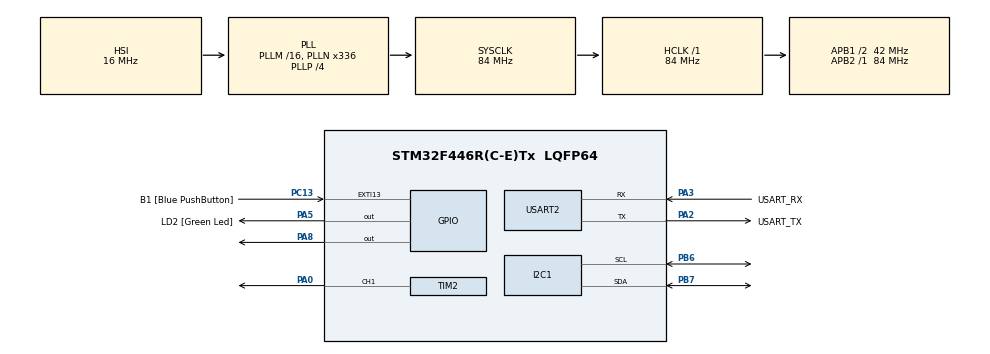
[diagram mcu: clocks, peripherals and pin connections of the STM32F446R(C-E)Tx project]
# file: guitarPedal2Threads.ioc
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FREERTOS.Tasks01=blinker,24,128,StartBlinker,Default,NULL,Dynamic,NULL,NULL;oled,8,128,StartOled,Default,NULL,Dynamic,NULL,NULL
FREERTOS.configTICK_RATE_HZ=1000
I2C1.I2C_Mode=I2C_Fast
Mcu.Family=STM32F4
Mcu.Name=STM32F446R(C-E)Tx
Mcu.Package=LQFP64
NVIC.PriorityGroup=NVIC_PRIORITYGROUP_4
NVIC.TIM6_DAC_IRQn=true\:15\:0\:false\:false\:true\:false\:false\:true\:true
NVIC.TimeBase=TIM6_DAC_IRQn
NVIC.TimeBaseIP=TIM6
PA0-WKUP.Signal=S_TIM2_CH1_ETR
PA13.GPIO_Label=TMS
PA13.Mode=Serial_Wire
PA13.Signal=SYS_JTMS-SWDIO
PA14.GPIO_Label=TCK
PA14.Mode=Serial_Wire
PA14.Signal=SYS_JTCK-SWCLK
PA2.GPIO_Label=USART_TX
PA2.Mode=Asynchronous
PA2.Signal=USART2_TX
PA3.GPIO_Label=USART_RX
PA3.Mode=Asynchronous
PA3.Signal=USART2_RX
PA5.GPIO_Label=LD2 [Green Led]
PA5.Signal=GPIO_Output
PA8.Signal=GPIO_Output
PB3.GPIO_Label=SWO
PB3.Signal=SYS_JTDO-SWO
PB6.Mode=I2C
PB6.Signal=I2C1_SCL
PB7.Mode=I2C
PB7.Signal=I2C1_SDA
PC13.GPIO_Label=B1 [Blue PushButton]
PC13.GPIO_ModeDefaultEXTI=GPIO_MODE_IT_FALLING
PC13.Signal=GPXTI13
PC14-OSC32_IN.Mode=LSE-External-Oscillator
PC14-OSC32_IN.Signal=RCC_OSC32_IN
PC15-OSC32_OUT.Mode=LSE-External-Oscillator
PC15-OSC32_OUT.Signal=RCC_OSC32_OUT
PH0-OSC_IN.Mode=HSE-External-Oscillator
PH0-OSC_IN.Signal=RCC_OSC_IN
PH1-OSC_OUT.Mode=HSE-External-Oscillator
PH1-OSC_OUT.Signal=RCC_OSC_OUT
ProjectManager.HeapSize=0x200
ProjectManager.StackSize=0x400
ProjectManager.TargetToolchain=STM32CubeIDE
RCC.48MHZClocksFreq_Value=84000000
RCC.AHBFreq_Value=84000000
RCC.APB1CLKDivider=RCC_HCLK_DIV2
RCC.APB1Freq_Value=42000000
RCC.APB1TimFreq_Value=84000000
RCC.APB2Freq_Value=84000000
RCC.APB2TimFreq_Value=84000000
RCC.CortexFreq_Value=84000000
RCC.FLatency-AdvancedSettings=FLASH_LATENCY_2
RCC.HCLKFreq_Value=84000000
RCC.HSE_VALUE=8000000
RCC.HSI_VALUE=16000000
RCC.PLLN=336
RCC.PLLP=RCC_PLLP_DIV4
RCC.SYSCLKFreq_VALUE=84000000
RCC.SYSCLKSource=RCC_SYSCLKSOURCE_PLLCLK
RCC.USBFreq_Value=168000000
RCC.VCOOutputFreq_Value=336000000
SH.S_TIM2_CH1_ETR.0=TIM2_CH1,PWM Generation1 CH1
TIM2.AutoReloadPreload=TIM_AUTORELOAD_PRELOAD_ENABLE
TIM2.Channel-PWM\ Generation1\ CH1=TIM_CHANNEL_1
TIM2.Period=255
TIM2.Pulse-PWM\ Generation1\ CH1=123
USART2.VirtualMode=VM_ASYNC
VP_FREERTOS_VS_CMSIS_V2.Mode=CMSIS_V2
VP_SYS_VS_tim6.Mode=TIM6
VP_TIM2_VS_ClockSourceINT.Mode=Internal
board=NUCLEO-F446RE

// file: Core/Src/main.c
/* USER CODE BEGIN Header */
/**
  ******************************************************************************
  * @file           : main.c
  * @brief          : Main program body
  ******************************************************************************
  * @attention
  *
  * Copyright (c) 2024 STMicroelectronics.
  * All rights reserved.
  *
  * This software is licensed under terms that can be found in the LICENSE file
  * in the root directory of this software component.
  * If no LICENSE file comes with this software, it is provided AS-IS.
  *
  ******************************************************************************
  */
/* USER CODE END Header */
#include "main.h"
#include "cmsis_os.h"

/* USER CODE BEGIN Includes */
#include "ssd1306.h"
#include "ssd1306_tests.h"
/* USER CODE END Includes */

I2C_HandleTypeDef hi2c1;

TIM_HandleTypeDef htim2;

UART_HandleTypeDef huart2;

/* Definitions for blinker */
osThreadId_t blinkerHandle;
const osThreadAttr_t blinker_attributes = {
  .name = "blinker",
  .stack_size = 128 * 4,
  .priority = (osPriority_t) osPriorityNormal,
};
/* Definitions for oled */
osThreadId_t oledHandle;
const osThreadAttr_t oled_attributes = {
  .name = "oled",
  .stack_size = 128 * 4,
  .priority = (osPriority_t) osPriorityLow,
};

const unsigned char epd_bitmap_catFrame0 []  = {
	0x00, 0x00, 0x00, 0x00, 0x00, 0x00, 0x00, 0x00, 0x00, 0x00, 0x00, 0x00, 0x07, 0x00, 0x00, 0x00,
	0x00, 0x00, 0x00, 0x00, 0x00, 0x00, 0x00, 0x00, 0x00, 0x00, 0x00, 0x00, 0x0f, 0x80, 0x00, 0x00,
	0x00, 0x00, 0x00, 0x00, 0x00, 0x00, 0x00, 0x00, 0x00, 0x00, 0x00, 0x00, 0x0f, 0x80, 0x00, 0x00,
	0x00, 0x00, 0x00, 0x00, 0x00, 0x00, 0x00, 0x00, 0x00, 0x00, 0x00, 0x00, 0x07, 0x00, 0x00, 0x00,
	0x00, 0x00, 0x00, 0x00, 0x00, 0x00, 0x00, 0x00, 0x00, 0x00, 0x00, 0x00, 0x00, 0x00, 0x00, 0x00,
	0x00, 0x00, 0x00, 0x00, 0x00, 0x00, 0x00, 0x00, 0x00, 0x00, 0x00, 0x00, 0x00, 0x00, 0x00, 0x00,
	0x00, 0x00, 0x00, 0x00, 0x00, 0x00, 0x00, 0x00, 0x00, 0x00, 0x00, 0x00, 0x00, 0x00, 0x00, 0x00,
	0x00, 0x00, 0x00, 0x00, 0x00, 0x00, 0x00, 0x00, 0x00, 0x00, 0x00, 0x00, 0x00, 0x00, 0x00, 0x00,
	0x00, 0x00, 0x00, 0x00, 0x00, 0x00, 0x00, 0x00, 0x00, 0x00, 0x00, 0x00, 0x00, 0x00, 0x00, 0x00,
	0x00, 0x00, 0x00, 0x00, 0x00, 0x00, 0x00, 0x00, 0x00, 0x00, 0x00, 0x00, 0x00, 0x00, 0x00, 0x00,
	0x00, 0x00, 0x00, 0x00, 0x00, 0x00, 0x00, 0x00, 0x00, 0x00, 0x00, 0x00, 0x00, 0x00, 0x00, 0x00,
	0x00, 0x00, 0x01, 0xff, 0xff, 0xf0, 0x00, 0x00, 0x00, 0x00, 0x00, 0x00, 0x00, 0x00, 0x00, 0x00,
	0x00, 0x00, 0x07, 0xff, 0xff, 0xf0, 0x00, 0x00, 0x00, 0x00, 0x00, 0x00, 0x00, 0x00, 0x00, 0x00,
	0xff, 0xff, 0xff, 0xff, 0xff, 0xcf, 0xff, 0xff, 0xff, 0xff, 0xff, 0xf8, 0x00, 0x00, 0x00, 0x00,
	0xff, 0xff, 0xff, 0xff, 0xff, 0xcf, 0xff, 0xff, 0xff, 0xff, 0xff, 0xf8, 0x00, 0x00, 0x00, 0x00,
	0xff, 0xff, 0xff, 0xff, 0xfe, 0x7f, 0xff, 0xff, 0xff, 0xff, 0xff, 0xfe, 0x00, 0x00, 0x00, 0x00,
	0xff, 0xff, 0xff, 0xff, 0xfe, 0x3f, 0xff, 0xff, 0xff, 0xff, 0xff, 0xff, 0x00, 0x00, 0x00, 0x00,
	0xff, 0xff, 0xff, 0xff, 0xfe, 0x7f, 0xff, 0xff, 0xff, 0xff, 0xff, 0xff, 0x00, 0x00, 0x00, 0x00,
	0xff, 0xff, 0xff, 0xff, 0xfe, 0x3f, 0xff, 0xff, 0xff, 0xff, 0xff, 0xff, 0x00, 0x00, 0x00, 0x00,
	0xff, 0xff, 0xff, 0xff, 0xfe, 0x3f, 0xff, 0xff, 0xff, 0xff, 0xff, 0xff, 0x00, 0x00, 0x00, 0x00,
	0xff, 0xff, 0xff, 0xff, 0xfe, 0x7f, 0xff, 0xff, 0xff, 0x8f, 0xff, 0xff, 0x00, 0x00, 0x00, 0x00,
	0xff, 0xff, 0xff, 0xff, 0xfe, 0x3f, 0xff, 0xff, 0xff, 0x83, 0xff, 0xff, 0x00, 0x00, 0x00, 0x00,
	0xff, 0xff, 0xff, 0xff, 0xfe, 0x7f, 0xff, 0xff, 0xff, 0xd3, 0xff, 0xff, 0x05, 0x40, 0x00, 0x00,
	0xff, 0xff, 0xff, 0xff, 0xfe, 0x3f, 0xff, 0xff, 0xfc, 0xfe, 0x7f, 0xff, 0x07, 0xe0, 0x00, 0x00,
	0xff, 0xff, 0xff, 0xff, 0xfe, 0x7f, 0xff, 0xff, 0xfc, 0xfe, 0xff, 0xff, 0x0f, 0xe0, 0x00, 0x00,
	0xff, 0xff, 0xff, 0xff, 0xfe, 0x7f, 0xff, 0xff, 0xfc, 0xff, 0xdf, 0xff, 0x3f, 0xe0, 0x00, 0x00,
	0xff, 0xff, 0xff, 0xff, 0xff, 0x7f, 0xff, 0xff, 0xfc, 0xff, 0xdf, 0xff, 0x3f, 0xe0, 0x00, 0x00,
	0xff, 0xff, 0xff, 0xff, 0xff, 0x3f, 0xff, 0xff, 0xfc, 0xff, 0xff, 0xff, 0xff, 0xe0, 0x00, 0x00,
	0xff, 0xff, 0xff, 0xc3, 0xff, 0x7f, 0xff, 0xff, 0xfc, 0xff, 0xf0, 0x01, 0xff, 0xe0, 0x00, 0x00,
	0xff, 0xff, 0xff, 0xc3, 0xff, 0x7f, 0xff, 0xff, 0xfc, 0xff, 0xf0, 0x01, 0xff, 0xe0, 0x00, 0x00,
	0xff, 0xff, 0xff, 0xff, 0xff, 0x3f, 0xff, 0xff, 0xfc, 0xff, 0xff, 0xff, 0xff, 0xc0, 0x00, 0x00,
	0xff, 0xff, 0xfe, 0x7e, 0x7f, 0x7f, 0xff, 0xff, 0xfc, 0xff, 0xff, 0xff, 0xff, 0xc0, 0x00, 0x00,
	0xff, 0xff, 0xfe, 0x7e, 0x7e, 0x3f, 0xff, 0xff, 0xff, 0xff, 0xff, 0xff, 0xff, 0xf8, 0x00, 0x00,
	0xff, 0xff, 0xfe, 0x7e, 0x00, 0x7f, 0xff, 0xff, 0xe3, 0xff, 0xff, 0xff, 0xff, 0xfc, 0x00, 0x00,
	0xff, 0xff, 0xfe, 0x7e, 0x00, 0x7f, 0xff, 0xff, 0xe3, 0xff, 0xff, 0xff, 0xff, 0xfc, 0x00, 0x00,
	0xff, 0xff, 0xff, 0xff, 0xfe, 0x3f, 0xff, 0xff, 0xe3, 0xff, 0xdf, 0xff, 0xfd, 0xfc, 0x00, 0x00,
	0xff, 0xff, 0xff, 0xcf, 0xfe, 0x7f, 0xff, 0xff, 0xe3, 0xff, 0xcf, 0xff, 0xf9, 0xfc, 0x00, 0x00,
	0xff, 0xff, 0xff, 0xdf, 0xfe, 0x7f, 0xff, 0xff, 0xe3, 0xff, 0xcf, 0xff, 0xf9, 0xfc, 0x00, 0x00,
	0xff, 0xff, 0xff, 0xf0, 0x7e, 0x7f, 0xff, 0xff, 0xe3, 0xfe, 0x0f, 0xf1, 0xc1, 0xfc, 0x00, 0x00,
	0xff, 0xff, 0xff, 0xf0, 0x7e, 0x7f, 0xff, 0xff, 0xe3, 0xfe, 0x0f, 0xf1, 0xc1, 0xfc, 0x00, 0x00,
	0xff, 0xff, 0xff, 0xf8, 0x7e, 0x7f, 0xff, 0xff, 0xe3, 0xff, 0xff, 0xff, 0xff, 0xfc, 0x00, 0x00,
	0xff, 0xff, 0xff, 0xff, 0xc0, 0x7f, 0xff, 0xff, 0xe3, 0xff, 0xff, 0xff, 0xff, 0xfc, 0x00, 0x00,
	0xff, 0xff, 0xff, 0xff, 0xf8, 0x7f, 0xff, 0xff, 0xe3, 0xff, 0xff, 0xff, 0xff, 0xfc, 0x00, 0x00,
	0xff, 0xff, 0xff, 0xff, 0xfe, 0x7f, 0xff, 0xff, 0xe3, 0xff, 0xcf, 0xcf, 0xc7, 0xfc, 0x00, 0x00,
	0xff, 0xff, 0xff, 0xff, 0xfe, 0x7f, 0xff, 0xff, 0xe3, 0xff, 0xcf, 0xcf, 0xc7, 0xfc, 0x00, 0x00,
	0xff, 0xff, 0xff, 0xff, 0xfe, 0x7f, 0xff, 0xff, 0xfe, 0xff, 0xc0, 0x00, 0x07, 0xe0, 0x00, 0x00,
	0xff, 0xff, 0xff, 0xff, 0xfe, 0x7f, 0xff, 0xff, 0xfc, 0xff, 0xc0, 0x00, 0x07, 0xc0, 0x00, 0x00,
	0xff, 0xff, 0xff, 0xff, 0xfe, 0x7f, 0xff, 0xff, 0xfe, 0xff, 0xff, 0xff, 0xff, 0xc0, 0x00, 0x00,
	0xff, 0xff, 0xff, 0xff, 0xf0, 0x7f, 0xff, 0xff, 0xff, 0x9f, 0xff, 0xff, 0xff, 0x00, 0x00, 0x00,
	0xff, 0xff, 0xff, 0xff, 0xf0, 0x7f, 0xff, 0xff, 0xff, 0x9f, 0xff, 0xff, 0xff, 0x00, 0x00, 0x00,
	0xff, 0xff, 0xff, 0xff, 0xce, 0x0f, 0xff, 0xff, 0xff, 0xf0, 0x00, 0x00, 0x00, 0x00, 0x00, 0x00,
	0xff, 0xff, 0xff, 0xff, 0xce, 0x0f, 0xff, 0xff, 0xff, 0xf0, 0x00, 0x00, 0x00, 0x00, 0x00, 0x00,
	0xff, 0xff, 0xff, 0xff, 0x8f, 0x0f, 0xff, 0xff, 0xff, 0xff, 0xff, 0xf8, 0x00, 0x00, 0x00, 0x00,
	0xff, 0xff, 0xff, 0xfe, 0x7f, 0xc7, 0xff, 0xff, 0xff, 0xff, 0xff, 0xfe, 0x00, 0x00, 0x00, 0x00,
	0xff, 0xff, 0xff, 0xfc, 0x7f, 0xc0, 0x00, 0x00, 0x00, 0x00, 0x00, 0x06, 0x00, 0x00, 0x00, 0x00,
	0xff, 0xff, 0xff, 0xfe, 0x7f, 0xc0, 0xf8, 0x00, 0x00, 0x0f, 0x80, 0x3e, 0x00, 0x00, 0x00, 0x00,
	0xff, 0xff, 0xfe, 0x00, 0x7e, 0x01, 0xf8, 0x00, 0x00, 0x1f, 0xc0, 0x7e, 0x00, 0x00, 0x00, 0x00,
	0xff, 0xff, 0xf8, 0x00, 0x3e, 0x01, 0xf8, 0x00, 0x00, 0x1f, 0xc0, 0x3e, 0x00, 0x00, 0x00, 0x00,
	0x00, 0x00, 0x00, 0x00, 0x00, 0x00, 0x00, 0x00, 0x00, 0x00, 0x00, 0x00, 0x00, 0x00, 0x00, 0x00,
	0x00, 0x00, 0x00, 0x00, 0x00, 0x00, 0x00, 0x00, 0x00, 0x00, 0x00, 0x00, 0x00, 0x00, 0x00, 0x00,
	0x00, 0x00, 0x00, 0x00, 0x00, 0x00, 0x00, 0x00, 0x00, 0x00, 0x00, 0x00, 0x00, 0x00, 0x00, 0x00,
	0x00, 0x00, 0x00, 0x00, 0x00, 0x00, 0x00, 0x00, 0x00, 0x00, 0x00, 0x00, 0x00, 0x00, 0x00, 0x00,
	0x00, 0x00, 0x00, 0x00, 0x00, 0x00, 0x00, 0x00, 0x00, 0x00, 0x00, 0x00, 0x00, 0x00, 0x00, 0x00,
	0x00, 0x00, 0x00, 0x00, 0x00, 0x00, 0x00, 0x00, 0x00, 0x00, 0x00, 0x00, 0x00, 0x00, 0x00, 0x00
};
// 'catFrame1', 128x64px
const unsigned char epd_bitmap_catFrame1 []  = {
	0x00, 0x00, 0x00, 0x00, 0x00, 0x00, 0x00, 0x00, 0x00, 0x00, 0x03, 0xff, 0x00, 0x00, 0x00, 0x00,
	0x00, 0x00, 0x00, 0x00, 0x00, 0x00, 0x00, 0x00, 0x00, 0x00, 0x03, 0xcf, 0x00, 0x00, 0x00, 0x00,
	0x00, 0x00, 0x00, 0x00, 0x00, 0x00, 0x00, 0x00, 0x00, 0x00, 0x03, 0xff, 0x00, 0x00, 0x00, 0x00,
	0x00, 0x00, 0x00, 0x00, 0x00, 0x00, 0x00, 0x00, 0x00, 0x00, 0x00, 0x78, 0x00, 0x00, 0x00, 0x00,
	0x00, 0x00, 0x00, 0x00, 0x00, 0x00, 0x00, 0x00, 0x00, 0x00, 0x00, 0x78, 0x00, 0x00, 0x00, 0x00,
	0x00, 0x00, 0x00, 0x00, 0x00, 0x00, 0x00, 0x00, 0x00, 0x00, 0x00, 0x30, 0x00, 0x00, 0x00, 0x00,
	0x00, 0x00, 0x00, 0x00, 0x00, 0x00, 0x00, 0x00, 0x00, 0x00, 0x00, 0x00, 0x00, 0x00, 0x00, 0x00,
	0x00, 0x00, 0x00, 0x00, 0x00, 0x00, 0x00, 0x00, 0x00, 0x00, 0x00, 0x00, 0x00, 0x00, 0x00, 0x00,
	0x00, 0x00, 0x00, 0x00, 0x00, 0x00, 0x00, 0x00, 0x00, 0x00, 0x00, 0x00, 0x00, 0x00, 0x00, 0x00,
	0x00, 0x00, 0x00, 0x00, 0x00, 0x00, 0x00, 0x00, 0x00, 0x00, 0x00, 0x00, 0x00, 0x00, 0x00, 0x00,
	0x00, 0x00, 0x00, 0x00, 0x00, 0x07, 0xff, 0xff, 0xff, 0xff, 0xff, 0xf8, 0x00, 0x00, 0x00, 0x00,
	0xff, 0xff, 0xe8, 0x00, 0x00, 0x0f, 0xff, 0xff, 0xff, 0xff, 0xff, 0xf8, 0x00, 0x00, 0x00, 0x00,
	0xff, 0xff, 0xf0, 0x02, 0x08, 0x3f, 0xff, 0xff, 0xff, 0xff, 0xff, 0xfe, 0x00, 0x00, 0x00, 0x00,
	0xff, 0xff, 0xff, 0xff, 0xfc, 0x7f, 0xff, 0xff, 0xff, 0xff, 0xff, 0xff, 0x00, 0x00, 0x00, 0x00,
	0xff, 0xff, 0xff, 0xff, 0xfe, 0x7f, 0xff, 0xff, 0xff, 0xff, 0xff, 0xff, 0x00, 0x00, 0x00, 0x00,
	0xff, 0xff, 0xff, 0xff, 0xfe, 0x7f, 0xff, 0xff, 0xff, 0xff, 0xff, 0xff, 0x00, 0x00, 0x00, 0x00,
	0xff, 0xff, 0xff, 0xff, 0xfe, 0x7f, 0xff, 0xff, 0xff, 0xff, 0xff, 0xff, 0x00, 0x00, 0x00, 0x00,
	0xff, 0xff, 0xff, 0xff, 0xfe, 0x7f, 0xff, 0xff, 0xff, 0xff, 0xff, 0xff, 0x00, 0x00, 0x00, 0x00,
	0xff, 0xff, 0xff, 0xff, 0xfe, 0x7f, 0xff, 0xff, 0xff, 0xff, 0xff, 0xff, 0x00, 0x00, 0x00, 0x00,
	0xff, 0xff, 0xff, 0xff, 0xfe, 0x7f, 0xff, 0xff, 0xff, 0xff, 0xff, 0xff, 0x00, 0x00, 0x00, 0x00,
	0xff, 0xff, 0xff, 0xff, 0xfe, 0x7f, 0xff, 0xff, 0xff, 0xff, 0xff, 0xff, 0x00, 0x00, 0x00, 0x00,
	0xff, 0xff, 0xff, 0xff, 0xfe, 0x7f, 0xff, 0xff, 0xff, 0xc3, 0xff, 0xff, 0x00, 0x00, 0x00, 0x00,
	0xff, 0xff, 0xff, 0xff, 0xfe, 0x7f, 0xff, 0xff, 0xff, 0xd3, 0xff, 0xff, 0x00, 0x00, 0x00, 0x00,
	0xff, 0xff, 0xff, 0xff, 0xfe, 0x7f, 0xff, 0xff, 0xfc, 0x7e, 0x7f, 0xff, 0x07, 0xc0, 0x00, 0x00,
	0xff, 0xff, 0xff, 0xff, 0xfe, 0x7f, 0xff, 0xff, 0xfc, 0x7e, 0x7f, 0xff, 0x07, 0xc0, 0x00, 0x00,
	0xff, 0xff, 0xfe, 0xff, 0xfe, 0x7f, 0xff, 0xff, 0xfc, 0x7f, 0xff, 0xff, 0x3f, 0xe0, 0x00, 0x00,
	0xff, 0xff, 0xfe, 0x00, 0x7e, 0x7f, 0xff, 0xff, 0xfc, 0x7f, 0xcf, 0xff, 0x3f, 0xe0, 0x00, 0x00,
	0xff, 0xff, 0xfe, 0x00, 0x7e, 0x7f, 0xff, 0xff, 0xfc, 0x7f, 0xcf, 0xff, 0x3f, 0xe0, 0x00, 0x00,
	0xff, 0xff, 0xfe, 0x7e, 0x0f, 0x7f, 0xff, 0xff, 0xfc, 0x7f, 0xf0, 0x01, 0xff, 0xe0, 0x00, 0x00,
	0xff, 0xff, 0xfe, 0x7e, 0x0e, 0x7f, 0xff, 0xff, 0xfc, 0x7f, 0xf0, 0x01, 0xff, 0xe0, 0x00, 0x00,
	0xff, 0xff, 0xfe, 0x3f, 0x86, 0x7f, 0xff, 0xff, 0xfc, 0x7f, 0xff, 0xff, 0xff, 0xc0, 0x00, 0x00,
	0xff, 0xff, 0xfe, 0x1f, 0xc0, 0x7f, 0xff, 0xff, 0xfc, 0x7f, 0xff, 0xff, 0xff, 0xc0, 0x00, 0x00,
	0xff, 0xff, 0xff, 0x8f, 0xd0, 0x7f, 0xff, 0xff, 0xff, 0xff, 0xff, 0xff, 0xff, 0xf8, 0x00, 0x00,
	0xff, 0xff, 0xff, 0xc1, 0xf8, 0x7f, 0xff, 0xff, 0xe3, 0xff, 0xff, 0xff, 0xff, 0xfc, 0x00, 0x00,
	0xff, 0xff, 0xff, 0xc1, 0xf8, 0x7f, 0xff, 0xff, 0xe3, 0xff, 0xff, 0xff, 0xff, 0xfc, 0x00, 0x00,
	0xff, 0xff, 0xff, 0xe1, 0xfe, 0x7f, 0xff, 0xff, 0xe3, 0xff, 0xff, 0xff, 0xff, 0xfc, 0x00, 0x00,
	0xff, 0xff, 0xff, 0xf0, 0x7e, 0x7f, 0xff, 0xff, 0xe3, 0xff, 0xcf, 0xff, 0xf8, 0xfc, 0x00, 0x00,
	0xff, 0xff, 0xff, 0xf0, 0x3e, 0x7f, 0xff, 0xff, 0xe3, 0xff, 0xcf, 0xff, 0xf8, 0xfc, 0x00, 0x00,
	0xff, 0xff, 0xff, 0xfe, 0x00, 0x7f, 0xff, 0xff, 0xe3, 0xfe, 0x0f, 0xf9, 0xe0, 0xfc, 0x00, 0x00,
	0xff, 0xff, 0xff, 0xfe, 0x00, 0x7f, 0xff, 0xff, 0xe3, 0xfe, 0x0f, 0xf9, 0xc0, 0xfc, 0x00, 0x00,
	0xff, 0xff, 0xff, 0xff, 0xf8, 0x7f, 0xff, 0xff, 0xe3, 0xff, 0xff, 0xff, 0xff, 0xfc, 0x00, 0x00,
	0xff, 0xff, 0xff, 0xff, 0xf8, 0x7f, 0xff, 0xff, 0xe3, 0xff, 0xff, 0xff, 0xff, 0xfc, 0x00, 0x00,
	0xff, 0xff, 0xff, 0xff, 0xf8, 0x7f, 0xff, 0xff, 0xe3, 0xff, 0xff, 0xff, 0xff, 0xfc, 0x00, 0x00,
	0xff, 0xff, 0xff, 0xff, 0xfe, 0x7f, 0xff, 0xff, 0xe3, 0xff, 0xcf, 0xcf, 0xc7, 0xfc, 0x00, 0x00,
	0xff, 0xff, 0xff, 0xff, 0xfe, 0x7f, 0xff, 0xff, 0xe3, 0xff, 0xcf, 0xcf, 0xc7, 0xfc, 0x00, 0x00,
	0xff, 0xff, 0xff, 0xff, 0xfe, 0x7f, 0xff, 0xff, 0xff, 0xff, 0xcf, 0xc7, 0xc7, 0xfc, 0x00, 0x00,
	0xff, 0xff, 0xff, 0xff, 0xfe, 0x7f, 0xff, 0xff, 0xfc, 0x7f, 0xc0, 0x00, 0x07, 0xc0, 0x00, 0x00,
	0xff, 0xff, 0xff, 0xff, 0xfe, 0x3f, 0xff, 0xff, 0xff, 0xff, 0xff, 0xf9, 0xef, 0xc0, 0x00, 0x00,
	0xff, 0xff, 0xff, 0xff, 0xf8, 0x0f, 0xff, 0xff, 0xff, 0x9f, 0xff, 0xff, 0xff, 0x00, 0x00, 0x00,
	0xff, 0xff, 0xff, 0xff, 0xf8, 0x0f, 0xff, 0xff, 0xff, 0x8f, 0xff, 0xff, 0xff, 0x00, 0x00, 0x00,
	0xff, 0xff, 0xff, 0xff, 0xcf, 0xf8, 0x74, 0xd5, 0xff, 0x00, 0x00, 0x00, 0x00, 0x00, 0x00, 0x00,
	0xff, 0xff, 0xff, 0xff, 0xcf, 0xf8, 0x00, 0x00, 0x00, 0x00, 0x00, 0x00, 0x00, 0x00, 0x00, 0x00,
	0xff, 0xff, 0xff, 0xff, 0x8f, 0xf8, 0x00, 0x00, 0x00, 0x00, 0x00, 0x00, 0x00, 0x00, 0x00, 0x00,
	0xff, 0xff, 0xff, 0xff, 0x8f, 0xe0, 0x07, 0xe0, 0x00, 0x03, 0xf0, 0x07, 0xc0, 0x00, 0x00, 0x00,
	0xff, 0xff, 0xff, 0xff, 0x8f, 0xc0, 0x07, 0xe0, 0x00, 0x03, 0xf8, 0x07, 0xc0, 0x00, 0x00, 0x00,
	0xf7, 0xfb, 0xff, 0xff, 0x87, 0xc0, 0x03, 0xe0, 0x00, 0x01, 0xf0, 0x07, 0xc0, 0x00, 0x00, 0x00,
	0x00, 0x00, 0x0f, 0xff, 0x80, 0x00, 0x00, 0x00, 0x00, 0x00, 0x00, 0x00, 0x00, 0x00, 0x00, 0x00,
	0x00, 0x00, 0x07, 0xff, 0x80, 0x00, 0x00, 0x00, 0x00, 0x00, 0x00, 0x00, 0x00, 0x00, 0x00, 0x00,
	0x00, 0x00, 0x00, 0x00, 0x00, 0x00, 0x00, 0x00, 0x00, 0x00, 0x00, 0x00, 0x00, 0x00, 0x00, 0x00,
	0x00, 0x00, 0x00, 0x00, 0x00, 0x00, 0x00, 0x00, 0x00, 0x00, 0x00, 0x00, 0x00, 0x00, 0x00, 0x00,
	0x00, 0x00, 0x00, 0x00, 0x00, 0x00, 0x00, 0x00, 0x00, 0x00, 0x00, 0x00, 0x00, 0x00, 0x00, 0x00,
	0x00, 0x00, 0x00, 0x00, 0x00, 0x00, 0x00, 0x00, 0x00, 0x00, 0x00, 0x00, 0x00, 0x00, 0x00, 0x00,
	0x00, 0x00, 0x00, 0x00, 0x00, 0x00, 0x00, 0x00, 0x00, 0x00, 0x00, 0x00, 0x00, 0x00, 0x00, 0x00,
	0x00, 0x00, 0x00, 0x00, 0x00, 0x00, 0x00, 0x00, 0x00, 0x00, 0x00, 0x00, 0x00, 0x00, 0x00, 0x00
};
// 'catFrame3', 128x64px
const unsigned char epd_bitmap_catFrame3 []  = {
	0x00, 0x00, 0xf0, 0x00, 0x78, 0x00, 0x00, 0x00, 0x00, 0x00, 0x00, 0x00, 0x00, 0x00, 0x00, 0x00,
	0x00, 0x00, 0xf0, 0x00, 0xf8, 0x00, 0x00, 0x00, 0x00, 0x00, 0x00, 0x00, 0x00, 0x00, 0x00, 0x00,
	0x00, 0x00, 0xf0, 0x00, 0xf8, 0x00, 0x00, 0x00, 0x00, 0x00, 0x00, 0x00, 0x00, 0x00, 0x00, 0x00,
	0x00, 0x00, 0xe0, 0x00, 0x70, 0x00, 0x00, 0x00, 0x00, 0x00, 0x00, 0x00, 0x00, 0x00, 0x00, 0x00,
	0x00, 0x00, 0x00, 0x00, 0x00, 0x00, 0x00, 0x00, 0x00, 0x00, 0x00, 0x00, 0x00, 0x00, 0x00, 0x00,
	0x00, 0x00, 0x1c, 0x03, 0xc0, 0x00, 0x00, 0x00, 0x00, 0x00, 0x00, 0x00, 0x00, 0x00, 0x00, 0x00,
	0x00, 0x00, 0x1c, 0x03, 0xc0, 0x00, 0x00, 0x00, 0x00, 0x00, 0x00, 0x00, 0x00, 0x00, 0x00, 0x00,
	0x00, 0x00, 0x1c, 0xf3, 0xc0, 0x00, 0x00, 0x00, 0x00, 0x00, 0x00, 0x00, 0x00, 0x00, 0x00, 0x00,
	0x00, 0x00, 0x00, 0xf0, 0x00, 0x00, 0x00, 0x00, 0x00, 0x00, 0x00, 0x00, 0x00, 0x00, 0x00, 0x00,
	0x00, 0x00, 0x00, 0xf0, 0x00, 0x00, 0x00, 0x00, 0x00, 0x00, 0x00, 0x00, 0x00, 0x00, 0x00, 0x00,
	0x00, 0x00, 0x02, 0xf8, 0x41, 0x00, 0x00, 0x00, 0x00, 0x00, 0x00, 0x00, 0x00, 0x00, 0x00, 0x00,
	0x80, 0x00, 0x03, 0xfd, 0xff, 0xd0, 0x00, 0x00, 0x00, 0x00, 0x00, 0x00, 0x00, 0x00, 0x00, 0x00,
	0xc0, 0x00, 0x0b, 0xff, 0xff, 0xe0, 0x00, 0x00, 0x00, 0x00, 0x00, 0x00, 0x00, 0x00, 0x00, 0x00,
	0xff, 0xff, 0xff, 0xff, 0xff, 0xcf, 0xff, 0xff, 0xff, 0xff, 0xff, 0xf8, 0x00, 0x00, 0x00, 0x00,
	0xff, 0xff, 0xff, 0xff, 0xff, 0xcf, 0xff, 0xff, 0xff, 0xff, 0xff, 0xf8, 0x00, 0x00, 0x00, 0x00,
	0xff, 0xff, 0xff, 0xff, 0xfe, 0x7f, 0xff, 0xff, 0xff, 0xff, 0xff, 0xff, 0x00, 0x00, 0x00, 0x00,
	0xff, 0xff, 0xff, 0xff, 0xfc, 0x7f, 0xff, 0xff, 0xff, 0xff, 0xff, 0xff, 0x00, 0x00, 0x00, 0x00,
	0xff, 0xff, 0xff, 0xff, 0xfe, 0x7f, 0xff, 0xff, 0xff, 0xff, 0xff, 0xff, 0x00, 0x00, 0x00, 0x00,
	0xff, 0xff, 0xff, 0xff, 0xfe, 0x7f, 0xff, 0xff, 0xff, 0xff, 0xff, 0xff, 0x00, 0x00, 0x00, 0x00,
	0xff, 0xff, 0xff, 0xff, 0xfe, 0x7f, 0xff, 0xff, 0xff, 0xff, 0xff, 0xff, 0x00, 0x00, 0x00, 0x00,
	0xff, 0xff, 0xff, 0xff, 0xfe, 0x7f, 0xff, 0xff, 0xff, 0xff, 0xff, 0xff, 0x00, 0x00, 0x00, 0x00,
	0xff, 0xff, 0xff, 0xff, 0xfe, 0x7f, 0xff, 0xff, 0xff, 0xff, 0xff, 0xff, 0x00, 0x00, 0x00, 0x00,
	0xff, 0xff, 0xff, 0xff, 0xfe, 0x7f, 0xff, 0xff, 0xff, 0xff, 0xff, 0xff, 0x00, 0x00, 0x00, 0x00,
	0xff, 0xff, 0xff, 0xff, 0xfe, 0x7f, 0xff, 0xff, 0xff, 0xf0, 0x7f, 0xff, 0x00, 0x00, 0x00, 0x00,
	0xff, 0xff, 0xff, 0xff, 0xfe, 0x7f, 0xff, 0xff, 0xff, 0xf0, 0x7f, 0xff, 0x00, 0x00, 0x00, 0x00,
	0xff, 0xff, 0xff, 0xff, 0xff, 0x7f, 0xff, 0xff, 0xff, 0xff, 0xff, 0xff, 0x00, 0xf8, 0x00, 0x00,
	0xff, 0xff, 0xff, 0xff, 0xfe, 0x7f, 0xff, 0xff, 0xff, 0x9f, 0xcf, 0xff, 0x00, 0xfc, 0x00, 0x00,
	0xff, 0xff, 0xff, 0xff, 0xff, 0x7f, 0xff, 0xff, 0xff, 0x9f, 0xff, 0xff, 0x03, 0xfc, 0x00, 0x00,
	0xff, 0xff, 0xff, 0xff, 0xfe, 0x7f, 0xff, 0xff, 0xff, 0x9f, 0xf3, 0xff, 0x07, 0xfc, 0x00, 0x00,
	0xff, 0xff, 0xff, 0xff, 0xff, 0x7f, 0xff, 0xff, 0xff, 0x9f, 0xf3, 0xff, 0x07, 0xfc, 0x00, 0x00,
	0xff, 0xff, 0xff, 0xff, 0xff, 0x7f, 0xff, 0xff, 0xff, 0x9f, 0xff, 0xfe, 0x3f, 0xfc, 0x00, 0x00,
	0xff, 0xff, 0xff, 0xff, 0xfe, 0x7f, 0xff, 0xff, 0xff, 0x9f, 0xfe, 0x00, 0x3f, 0xfc, 0x00, 0x00,
	0xff, 0xff, 0xff, 0xff, 0xfe, 0x7f, 0xff, 0xff, 0xff, 0x9f, 0xff, 0x7f, 0x7f, 0xfc, 0x00, 0x00,
	0xff, 0xff, 0xff, 0xff, 0xfe, 0x7f, 0xff, 0xff, 0xff, 0x9f, 0xff, 0xff, 0xff, 0xfc, 0x00, 0x00,
	0xff, 0xff, 0xff, 0xff, 0xfe, 0x7f, 0xff, 0xff, 0xff, 0x9f, 0xff, 0xff, 0xff, 0xfc, 0x00, 0x00,
	0xff, 0xff, 0xff, 0xff, 0xfe, 0x7f, 0xff, 0xff, 0xff, 0xff, 0xff, 0xff, 0xff, 0xff, 0x00, 0x00,
	0xff, 0xff, 0xff, 0xff, 0xc0, 0x7f, 0xff, 0xff, 0xfc, 0x7f, 0xff, 0xff, 0xff, 0xff, 0x00, 0x00,
	0xff, 0xff, 0xff, 0xff, 0xc0, 0x7f, 0xff, 0xff, 0xfc, 0x7f, 0xff, 0xff, 0xff, 0xff, 0x00, 0x00,
	0xff, 0xff, 0xff, 0xf0, 0x7e, 0x7f, 0xff, 0xff, 0xfc, 0x7f, 0xf3, 0xff, 0xff, 0x3f, 0x80, 0x00,
	0xff, 0xff, 0xff, 0xf0, 0x3e, 0x7f, 0xff, 0xff, 0xfc, 0x7f, 0xf3, 0xff, 0xff, 0x3f, 0x80, 0x00,
	0xff, 0xff, 0xff, 0xff, 0xfe, 0x7f, 0xff, 0xff, 0xfc, 0x7f, 0xf3, 0xff, 0xff, 0x3f, 0x00, 0x00,
	0xff, 0xff, 0xff, 0x9f, 0xfe, 0x7f, 0xff, 0xff, 0xfc, 0x7f, 0x83, 0xfe, 0x38, 0x3f, 0x80, 0x00,
	0xff, 0xff, 0xff, 0xbf, 0xfe, 0x7f, 0xff, 0xff, 0xfc, 0x7f, 0xc3, 0xff, 0x79, 0x3f, 0x80, 0x00,
	0xff, 0xff, 0xfc, 0x7e, 0x00, 0x7f, 0xff, 0xff, 0xfc, 0x7f, 0xff, 0xff, 0xff, 0xff, 0x80, 0x00,
	0xff, 0xff, 0xfc, 0x7e, 0x00, 0x7f, 0xff, 0xff, 0xfc, 0x7f, 0xff, 0xff, 0xff, 0xff, 0x80, 0x00,
	0xff, 0xff, 0xfc, 0x7e, 0x00, 0x7f, 0xff, 0xff, 0xfc, 0x7f, 0xfb, 0xfb, 0xf9, 0xff, 0x80, 0x00,
	0xff, 0xff, 0xfc, 0x7e, 0x3e, 0x7f, 0xff, 0xff, 0xfc, 0x7f, 0xf3, 0xf9, 0xf8, 0xff, 0x80, 0x00,
	0xff, 0xff, 0xfe, 0x7e, 0x7e, 0x3f, 0xff, 0xff, 0xff, 0xff, 0xf1, 0xf9, 0xf8, 0xff, 0x80, 0x00,
	0xff, 0xff, 0xff, 0x80, 0xfe, 0x3f, 0xff, 0xff, 0xff, 0x9f, 0xf0, 0x00, 0x00, 0xfc, 0x00, 0x00,
	0xff, 0xff, 0xff, 0x81, 0xfe, 0x3f, 0xff, 0xff, 0xff, 0x9f, 0xf0, 0x00, 0x00, 0xfc, 0x00, 0x00,
	0xff, 0xff, 0xff, 0xe7, 0xfe, 0x1f, 0xff, 0xff, 0xff, 0xf3, 0xff, 0xff, 0xff, 0xe0, 0x00, 0x00,
	0xff, 0xff, 0xff, 0xff, 0xfe, 0x0f, 0xff, 0xff, 0xff, 0xf3, 0xff, 0xff, 0xff, 0xe0, 0x00, 0x00,
	0xff, 0xff, 0xff, 0xff, 0xfc, 0x0f, 0xff, 0xff, 0xff, 0xf3, 0xff, 0xff, 0xff, 0xc0, 0x00, 0x00,
	0xff, 0xff, 0xff, 0xff, 0xf1, 0xff, 0xff, 0xff, 0xff, 0xe0, 0x00, 0x00, 0x00, 0x00, 0x00, 0x00,
	0xff, 0xff, 0xff, 0xff, 0xf1, 0xf0, 0x00, 0x00, 0x00, 0x00, 0x00, 0x00, 0x00, 0x00, 0x00, 0x00,
	0xff, 0xff, 0xff, 0xff, 0xf1, 0xf8, 0x07, 0xc0, 0x1f, 0x1c, 0x7c, 0x01, 0xf0, 0x00, 0x00, 0x00,
	0xff, 0xff, 0xfc, 0x00, 0x01, 0xf8, 0x07, 0xe0, 0x3f, 0x9e, 0x7e, 0x01, 0xf8, 0x00, 0x00, 0x00,
	0xff, 0xff, 0xfc, 0x00, 0x01, 0xf0, 0x07, 0xe0, 0x1f, 0xfe, 0x7e, 0x01, 0xf0, 0x00, 0x00, 0x00,
	0x00, 0x00, 0x00, 0x00, 0x00, 0x00, 0x00, 0x00, 0x01, 0xf4, 0x00, 0x00, 0x00, 0x00, 0x00, 0x00,
	0x00, 0x00, 0x00, 0x00, 0x00, 0x00, 0x00, 0x00, 0x00, 0xf0, 0x00, 0x00, 0x00, 0x00, 0x00, 0x00,
	0x00, 0x00, 0x00, 0x00, 0x00, 0x00, 0x00, 0x00, 0x00, 0xf0, 0x00, 0x00, 0x00, 0x00, 0x00, 0x00,
	0x00, 0x00, 0x00, 0x00, 0x00, 0x00, 0x00, 0x00, 0x00, 0xf0, 0x00, 0x00, 0x00, 0x00, 0x00, 0x00,
	0x00, 0x00, 0x00, 0x00, 0x00, 0x00, 0x00, 0x00, 0x00, 0xf0, 0x00, 0x00, 0x00, 0x00, 0x00, 0x00,
	0x00, 0x00, 0x00, 0x00, 0x00, 0x00, 0x00, 0x00, 0x00, 0xf0, 0x00, 0x00, 0x00, 0x00, 0x00, 0x00
};
// 'catFrame2', 128x64px
const unsigned char epd_bitmap_catFrame2 []  = {
	0x00, 0x00, 0x00, 0x00, 0x00, 0x3f, 0x38, 0xfc, 0x00, 0x00, 0x00, 0x00, 0x00, 0x00, 0x00, 0x00,
	0x00, 0x00, 0x00, 0x00, 0x00, 0x7f, 0x3c, 0xfc, 0x00, 0x00, 0x00, 0x00, 0x00, 0x00, 0x00, 0x00,
	0x00, 0x00, 0x00, 0x00, 0x00, 0x3f, 0x38, 0xfc, 0x00, 0x00, 0x00, 0x00, 0x00, 0x00, 0x00, 0x00,
	0x00, 0x00, 0x00, 0x00, 0x00, 0x00, 0x10, 0x00, 0x00, 0x00, 0x00, 0x00, 0x00, 0x00, 0x00, 0x00,
	0x00, 0x00, 0x00, 0x00, 0x00, 0x00, 0x00, 0x00, 0x00, 0x00, 0x00, 0x00, 0x00, 0x00, 0x00, 0x00,
	0x00, 0x00, 0x00, 0x00, 0x00, 0x00, 0x38, 0x00, 0x00, 0x00, 0x00, 0x00, 0x00, 0x00, 0x00, 0x00,
	0x00, 0x00, 0x00, 0x00, 0x00, 0x00, 0x3c, 0x00, 0x00, 0x00, 0x00, 0x00, 0x00, 0x00, 0x00, 0x00,
	0x00, 0x00, 0x00, 0x00, 0x00, 0x00, 0x3c, 0x00, 0x00, 0x00, 0x00, 0x00, 0x00, 0x00, 0x00, 0x00,
	0x00, 0x00, 0x00, 0x00, 0x00, 0x00, 0x3c, 0x00, 0x00, 0x00, 0x00, 0x00, 0x00, 0x00, 0x00, 0x00,
	0x00, 0x00, 0x00, 0x00, 0x00, 0x00, 0x3c, 0x00, 0x00, 0x00, 0x00, 0x00, 0x00, 0x00, 0x00, 0x00,
	0x00, 0x00, 0x02, 0x80, 0x00, 0x30, 0x38, 0x00, 0x00, 0x00, 0x00, 0x00, 0x00, 0x00, 0x00, 0x00,
	0xc0, 0x00, 0x07, 0xff, 0xff, 0xd8, 0x00, 0x00, 0x00, 0x00, 0x00, 0x00, 0x00, 0x00, 0x00, 0x00,
	0x7f, 0xff, 0xbf, 0xff, 0xff, 0xf8, 0x00, 0x00, 0x00, 0x00, 0x00, 0x00, 0x00, 0x00, 0x00, 0x00,
	0xff, 0xff, 0xff, 0xff, 0xff, 0xcf, 0xff, 0xff, 0xff, 0xff, 0xff, 0xf8, 0x00, 0x00, 0x00, 0x00,
	0xff, 0xff, 0xff, 0xff, 0xff, 0xef, 0xff, 0xff, 0xff, 0xff, 0xff, 0xf8, 0x00, 0x00, 0x00, 0x00,
	0xff, 0xff, 0xff, 0xff, 0xfe, 0xff, 0xff, 0xff, 0xff, 0xff, 0xff, 0xfe, 0x00, 0x00, 0x00, 0x00,
	0xff, 0xff, 0xff, 0xff, 0xfe, 0x7f, 0xff, 0xff, 0xff, 0xff, 0xff, 0xfe, 0x00, 0x00, 0x00, 0x00,
	0xff, 0xff, 0xff, 0xff, 0xfe, 0x3f, 0xff, 0xff, 0xff, 0xff, 0xff, 0xfe, 0x00, 0x00, 0x00, 0x00,
	0xff, 0xff, 0xff, 0xff, 0xfe, 0x3f, 0xff, 0xff, 0xff, 0xff, 0xff, 0xfe, 0x00, 0x00, 0x00, 0x00,
	0xff, 0xff, 0xff, 0xff, 0xfe, 0x3f, 0xff, 0xff, 0xff, 0xff, 0xff, 0xfe, 0x00, 0x00, 0x00, 0x00,
	0xff, 0xff, 0xff, 0xff, 0xfe, 0x3f, 0xff, 0xff, 0xff, 0xff, 0xff, 0xfe, 0x00, 0x00, 0x00, 0x00,
	0xff, 0xff, 0xff, 0xff, 0xfe, 0x3f, 0xff, 0xff, 0xff, 0xff, 0xff, 0xfe, 0x00, 0x00, 0x00, 0x00,
	0xff, 0xff, 0xff, 0xff, 0xfe, 0x3f, 0xff, 0xff, 0xff, 0xff, 0xff, 0xfe, 0x00, 0x00, 0x00, 0x00,
	0xff, 0xff, 0xff, 0xff, 0xfe, 0x3f, 0xff, 0xff, 0xff, 0xe0, 0x7f, 0xfe, 0x00, 0x00, 0x00, 0x00,
	0xff, 0xff, 0xff, 0xff, 0xfe, 0x3f, 0xff, 0xff, 0xff, 0xf0, 0x7f, 0xfe, 0x00, 0x00, 0x00, 0x00,
	0xff, 0xff, 0xff, 0xff, 0xff, 0x3f, 0xff, 0xff, 0xff, 0xff, 0xff, 0xff, 0x00, 0xf8, 0x00, 0x00,
	0xff, 0xff, 0xff, 0xff, 0xfe, 0x3f, 0xff, 0xff, 0xff, 0x9f, 0x8f, 0xfe, 0x00, 0xf8, 0x00, 0x00,
	0xff, 0xff, 0xff, 0xff, 0xfe, 0x3f, 0xff, 0xff, 0xff, 0x9f, 0xdf, 0xff, 0x01, 0xf8, 0x00, 0x00,
	0xff, 0xff, 0xff, 0xff, 0xfe, 0x3f, 0xff, 0xff, 0xff, 0x9f, 0xf3, 0xff, 0x07, 0xf8, 0x00, 0x00,
	0xff, 0xff, 0xff, 0xff, 0xfe, 0x3f, 0xff, 0xff, 0xff, 0x9f, 0xf3, 0xfe, 0x07, 0xf8, 0x00, 0x00,
	0xff, 0xff, 0xff, 0xff, 0xfe, 0x7f, 0xff, 0xff, 0xff, 0x9f, 0xff, 0xfe, 0x3f, 0xf8, 0x00, 0x00,
	0xff, 0xff, 0xff, 0xff, 0xfe, 0x3f, 0xff, 0xff, 0xff, 0x9f, 0xfe, 0x00, 0x3f, 0xf8, 0x00, 0x00,
	0xff, 0xff, 0xff, 0xff, 0xfe, 0x3f, 0xff, 0xff, 0xff, 0x9f, 0xfe, 0x00, 0x7f, 0xf8, 0x00, 0x00,
	0xff, 0xff, 0xff, 0xff, 0xfe, 0x3f, 0xff, 0xff, 0xff, 0x9f, 0xff, 0xff, 0xff, 0xf8, 0x00, 0x00,
	0xff, 0xff, 0xff, 0xff, 0xfe, 0x3f, 0xff, 0xff, 0xff, 0x9f, 0xff, 0xff, 0xff, 0xf8, 0x00, 0x00,
	0xff, 0xff, 0xff, 0xff, 0xfe, 0x3f, 0xff, 0xff, 0xff, 0xff, 0xff, 0xff, 0xff, 0xff, 0x00, 0x00,
	0xff, 0xff, 0xff, 0xff, 0xf8, 0x3f, 0xff, 0xff, 0xfc, 0x7f, 0xff, 0xff, 0xff, 0xff, 0x00, 0x00,
	0xff, 0xff, 0xff, 0xff, 0xf8, 0x3f, 0xff, 0xff, 0xfc, 0x7f, 0xff, 0xff, 0xff, 0xff, 0x00, 0x00,
	0xff, 0xff, 0xff, 0xf0, 0x00, 0x3f, 0xff, 0xff, 0xfc, 0x7f, 0xf1, 0xff, 0xff, 0x3f, 0x00, 0x00,
	0xff, 0xff, 0xff, 0xf0, 0x00, 0x3f, 0xff, 0xff, 0xfc, 0x7f, 0xf1, 0xff, 0xff, 0x3f, 0x00, 0x00,
	0xff, 0xff, 0xfe, 0xbf, 0xfe, 0x3f, 0xff, 0xff, 0xfc, 0x7f, 0xf1, 0xff, 0x3f, 0x3f, 0x00, 0x00,
	0xff, 0xff, 0xfc, 0x0f, 0xfe, 0x3f, 0xff, 0xff, 0xfc, 0x7f, 0x81, 0xfe, 0x38, 0x3f, 0x00, 0x00,
	0xff, 0xff, 0xfc, 0x1f, 0xfe, 0x3f, 0xff, 0xff, 0xfc, 0x7f, 0xc3, 0xff, 0x38, 0x3f, 0x00, 0x00,
	0xff, 0xff, 0xfc, 0x7f, 0xc0, 0x3f, 0xff, 0xff, 0xfc, 0x7f, 0xff, 0xff, 0xff, 0xff, 0x80, 0x00,
	0xff, 0xff, 0xfc, 0x7f, 0xc0, 0x3f, 0xff, 0xff, 0xfc, 0x7f, 0xff, 0xff, 0xff, 0xff, 0x80, 0x00,
	0xff, 0xff, 0xfe, 0x7d, 0x00, 0x3f, 0xff, 0xff, 0xfc, 0x7f, 0xf3, 0xf9, 0xf8, 0xff, 0x80, 0x00,
	0xff, 0xff, 0xff, 0x80, 0x06, 0x3f, 0xff, 0xff, 0xfc, 0x7f, 0xf1, 0xf1, 0xf8, 0xff, 0x80, 0x00,
	0xff, 0xff, 0xff, 0x80, 0x06, 0x3f, 0xff, 0xff, 0xff, 0xff, 0xf1, 0xf1, 0xf8, 0xff, 0x00, 0x00,
	0xff, 0xff, 0xff, 0xe0, 0x0e, 0x3f, 0xff, 0xff, 0xff, 0x9f, 0xf0, 0x00, 0x00, 0xfc, 0x00, 0x00,
	0xff, 0xff, 0xff, 0xff, 0xfe, 0x3f, 0xff, 0xff, 0xff, 0x9f, 0xf0, 0x00, 0x00, 0xf8, 0x00, 0x00,
	0xff, 0xff, 0xff, 0xff, 0xfe, 0x0f, 0xff, 0xff, 0xff, 0xf3, 0xff, 0xff, 0xff, 0xe0, 0x00, 0x00,
	0xff, 0xff, 0xff, 0xff, 0xfe, 0x0f, 0xff, 0xff, 0xff, 0xf3, 0xff, 0xff, 0xff, 0xc0, 0x00, 0x00,
	0xff, 0xff, 0xff, 0xff, 0xfe, 0x0f, 0xff, 0xff, 0xff, 0xe3, 0xff, 0xff, 0xff, 0xc0, 0x00, 0x00,
	0xff, 0xff, 0xff, 0xff, 0xfe, 0x30, 0x00, 0x00, 0x00, 0x00, 0x00, 0x00, 0x00, 0x00, 0x00, 0x00,
	0xff, 0xff, 0xff, 0xff, 0xfe, 0x30, 0x00, 0x00, 0x00, 0x00, 0x00, 0x00, 0x00, 0x00, 0x00, 0x00,
	0xff, 0xff, 0xff, 0xff, 0xfc, 0x38, 0x00, 0x00, 0x00, 0x00, 0x00, 0x06, 0x3c, 0x00, 0x00, 0x00,
	0xff, 0xff, 0xfc, 0x00, 0x00, 0x3e, 0x00, 0xfc, 0x00, 0x00, 0x0f, 0xc6, 0x3e, 0x00, 0x00, 0x00,
	0x5f, 0x7b, 0xbc, 0x00, 0x00, 0x3e, 0x00, 0xf8, 0x00, 0x00, 0x0f, 0xc6, 0x3e, 0x00, 0x00, 0x00,
	0x00, 0x00, 0x00, 0x00, 0x00, 0x00, 0x00, 0x00, 0x00, 0x00, 0x00, 0x00, 0x00, 0x00, 0x00, 0x00,
	0x00, 0x00, 0x00, 0x00, 0x00, 0x00, 0x00, 0x00, 0x00, 0x00, 0x00, 0x00, 0x00, 0x00, 0x00, 0x00,
	0x00, 0x00, 0x00, 0x00, 0x00, 0x00, 0x00, 0x00, 0x00, 0x00, 0x00, 0x00, 0x00, 0x00, 0x00, 0x00,
	0x00, 0x00, 0x00, 0x00, 0x00, 0x00, 0x00, 0x00, 0x00, 0x00, 0x00, 0x00, 0x00, 0x00, 0x00, 0x00,
	0x00, 0x00, 0x00, 0x00, 0x00, 0x00, 0x00, 0x00, 0x00, 0x00, 0x00, 0x00, 0x00, 0x00, 0x00, 0x00,
	0x00, 0x00, 0x00, 0x00, 0x00, 0x00, 0x00, 0x00, 0x00, 0x00, 0x00, 0x00, 0x00, 0x00, 0x00, 0x00
};
// 'catFrame4', 128x64px
const unsigned char epd_bitmap_catFrame4 []  = {
	0x00, 0xf0, 0x00, 0x00, 0x00, 0x00, 0x00, 0x00, 0x00, 0x00, 0x00, 0x00, 0x00, 0x00, 0x00, 0x00,
	0x00, 0xf0, 0x00, 0x00, 0x00, 0x00, 0x00, 0x00, 0x00, 0x00, 0x00, 0x00, 0x00, 0x00, 0x00, 0x00,
	0x00, 0xf0, 0x00, 0x00, 0x00, 0x00, 0x00, 0x00, 0x00, 0x00, 0x00, 0x00, 0x00, 0x00, 0x00, 0x00,
	0x00, 0xe0, 0x00, 0x00, 0x00, 0x00, 0x00, 0x00, 0x00, 0x00, 0x00, 0x00, 0x00, 0x00, 0x00, 0x00,
	0x00, 0x00, 0x00, 0x00, 0x00, 0x00, 0x00, 0x00, 0x00, 0x00, 0x00, 0x00, 0x00, 0x00, 0x00, 0x00,
	0x00, 0x00, 0x00, 0x00, 0x00, 0x00, 0x00, 0x00, 0x00, 0x00, 0x00, 0x00, 0x00, 0x00, 0x00, 0x00,
	0x00, 0x00, 0x00, 0x00, 0x00, 0x00, 0x00, 0x00, 0x00, 0x00, 0x00, 0x00, 0x00, 0x00, 0x00, 0x00,
	0xe0, 0x00, 0x00, 0x00, 0x00, 0x00, 0x00, 0x00, 0x00, 0x00, 0x00, 0x00, 0x00, 0x00, 0x00, 0x00,
	0xe0, 0x00, 0x00, 0x00, 0x00, 0x00, 0x00, 0x00, 0x00, 0x00, 0x00, 0x00, 0x00, 0x00, 0x00, 0x00,
	0xf0, 0x00, 0x00, 0x00, 0x00, 0x00, 0x00, 0x00, 0x00, 0x00, 0x00, 0x00, 0x00, 0x00, 0x00, 0x00,
	0xe0, 0x00, 0x10, 0x00, 0x00, 0x00, 0x00, 0x00, 0x00, 0x00, 0x00, 0x00, 0x00, 0x00, 0x00, 0x00,
	0xff, 0xff, 0xc2, 0x65, 0x60, 0x80, 0x00, 0x00, 0x00, 0x00, 0x00, 0x00, 0x00, 0x00, 0x00, 0x00,
	0xff, 0xff, 0xc0, 0x00, 0x00, 0x50, 0x00, 0x00, 0x00, 0x00, 0x00, 0x00, 0x00, 0x00, 0x00, 0x00,
	0xff, 0xff, 0xfb, 0xbf, 0xfe, 0xcf, 0xff, 0xff, 0xff, 0xff, 0xff, 0xf8, 0x00, 0x00, 0x00, 0x00,
	0xff, 0xff, 0xff, 0xff, 0xfe, 0xaf, 0xff, 0xff, 0xff, 0xff, 0xff, 0xf8, 0x00, 0x00, 0x00, 0x00,
	0xff, 0xff, 0xff, 0xff, 0xfe, 0x3f, 0xff, 0xff, 0xff, 0xff, 0xff, 0xfe, 0x00, 0x00, 0x00, 0x00,
	0xff, 0xff, 0xff, 0xff, 0xfe, 0x7f, 0xff, 0xff, 0xff, 0xff, 0xff, 0xff, 0x00, 0x00, 0x00, 0x00,
	0xff, 0xff, 0xff, 0xff, 0xfc, 0x3f, 0xff, 0xff, 0xff, 0xff, 0xff, 0xff, 0x00, 0x00, 0x00, 0x00,
	0xff, 0xff, 0xff, 0xff, 0xfa, 0x3f, 0xff, 0xff, 0xff, 0xff, 0xff, 0xff, 0x00, 0x00, 0x00, 0x00,
	0xff, 0xff, 0xff, 0xff, 0xfe, 0x3f, 0xff, 0xff, 0xff, 0xff, 0xff, 0xff, 0x00, 0x00, 0x00, 0x00,
	0xff, 0xff, 0xff, 0xff, 0xfe, 0x3f, 0xff, 0xff, 0xff, 0xff, 0xff, 0xff, 0x00, 0x00, 0x00, 0x00,
	0xff, 0xff, 0xff, 0xff, 0xfe, 0x3f, 0xff, 0xff, 0xff, 0xff, 0xff, 0xff, 0x00, 0x00, 0x00, 0x00,
	0xff, 0xff, 0xff, 0xff, 0xfe, 0x3f, 0xff, 0xff, 0xff, 0xff, 0xff, 0xff, 0x00, 0x00, 0x00, 0x00,
	0xff, 0xff, 0xff, 0xff, 0xfe, 0x3f, 0xff, 0xff, 0xff, 0x83, 0xff, 0xff, 0x00, 0x00, 0x00, 0x00,
	0xff, 0xff, 0xff, 0xff, 0xfe, 0x3f, 0xff, 0xff, 0xff, 0x83, 0xff, 0xff, 0x00, 0x00, 0x00, 0x00,
	0xff, 0xff, 0xff, 0xff, 0xfe, 0x3f, 0xff, 0xff, 0xff, 0xfd, 0xff, 0xff, 0x07, 0xc0, 0x00, 0x00,
	0xff, 0xff, 0xff, 0xff, 0xfe, 0x3f, 0xff, 0xff, 0xfc, 0xfe, 0x7f, 0xff, 0x07, 0xe0, 0x00, 0x00,
	0xff, 0xff, 0xff, 0xff, 0xff, 0x3f, 0xff, 0xff, 0xfc, 0xff, 0xff, 0xff, 0x3f, 0xc0, 0x00, 0x00,
	0xff, 0xff, 0xff, 0xff, 0xff, 0x3f, 0xff, 0xff, 0xfc, 0xff, 0xcf, 0xff, 0x3f, 0xc0, 0x00, 0x00,
	0xff, 0xff, 0xff, 0xff, 0xff, 0x3f, 0xff, 0xff, 0xfc, 0xff, 0xcf, 0xff, 0x3f, 0xe0, 0x00, 0x00,
	0xff, 0xff, 0xff, 0xff, 0xff, 0x3f, 0xff, 0xff, 0xfc, 0xff, 0xff, 0xff, 0xff, 0xc0, 0x00, 0x00,
	0xff, 0xff, 0xfe, 0x00, 0x7f, 0x3f, 0xff, 0xff, 0xfc, 0xff, 0xf0, 0x01, 0xff, 0xc0, 0x00, 0x00,
	0xff, 0xff, 0xff, 0xe4, 0x7e, 0x3f, 0xff, 0xff, 0xfc, 0xff, 0xfa, 0xfb, 0xff, 0xc0, 0x00, 0x00,
	0xff, 0xff, 0xf3, 0xfe, 0x00, 0x3f, 0xff, 0xff, 0xfc, 0xff, 0xff, 0xff, 0xff, 0xc0, 0x00, 0x00,
	0xff, 0xff, 0xf3, 0xfe, 0x00, 0x3f, 0xff, 0xff, 0xfc, 0xff, 0xff, 0xff, 0xff, 0xc0, 0x00, 0x00,
	0xff, 0xff, 0xf0, 0xff, 0xf0, 0x3f, 0xff, 0xff, 0xff, 0xff, 0xff, 0xff, 0xff, 0xf8, 0x00, 0x00,
	0xff, 0xff, 0xf0, 0x7f, 0xf0, 0x3f, 0xff, 0xff, 0xe3, 0xff, 0xff, 0xff, 0xff, 0xfc, 0x00, 0x00,
	0xff, 0xff, 0xff, 0xff, 0xfc, 0x3f, 0xff, 0xff, 0xe3, 0xff, 0xff, 0xff, 0xff, 0xfc, 0x00, 0x00,
	0xff, 0xff, 0xff, 0x80, 0x0e, 0x3f, 0xff, 0xff, 0xe3, 0xff, 0xcf, 0xff, 0xf9, 0xfc, 0x00, 0x00,
	0xff, 0xff, 0xff, 0xc0, 0x0e, 0x3f, 0xff, 0xff, 0xe3, 0xff, 0xcf, 0xff, 0xf9, 0xfc, 0x00, 0x00,
	0xff, 0xff, 0xff, 0xff, 0xc0, 0x7f, 0xff, 0xff, 0xe3, 0xff, 0x8f, 0xff, 0xf9, 0xfc, 0x00, 0x00,
	0xff, 0xff, 0xff, 0xff, 0xc0, 0x3f, 0xff, 0xff, 0xe3, 0xfe, 0x0f, 0xf1, 0xc1, 0xfc, 0x00, 0x00,
	0xff, 0xff, 0xff, 0xff, 0xf8, 0x3f, 0xff, 0xff, 0xe3, 0xfe, 0x1f, 0xfb, 0xe9, 0xfc, 0x00, 0x00,
	0xff, 0xff, 0xff, 0xff, 0xfe, 0x3f, 0xff, 0xff, 0xe3, 0xff, 0xff, 0xff, 0xff, 0xfc, 0x00, 0x00,
	0xff, 0xff, 0xff, 0xff, 0xfe, 0x3f, 0xff, 0xff, 0xe3, 0xff, 0xff, 0xff, 0xff, 0xfc, 0x00, 0x00,
	0xff, 0xff, 0xff, 0xff, 0xfe, 0x3f, 0xff, 0xff, 0xe3, 0xff, 0xdf, 0xcf, 0xc7, 0xfc, 0x00, 0x00,
	0xff, 0xff, 0xff, 0xff, 0xfe, 0x3f, 0xff, 0xff, 0xe3, 0xff, 0xcf, 0xcf, 0xc7, 0xf8, 0x00, 0x00,
	0xff, 0xff, 0xff, 0xff, 0xfe, 0x3f, 0xff, 0xff, 0xff, 0xff, 0xcf, 0xcf, 0xc7, 0xf8, 0x00, 0x00,
	0xff, 0xff, 0xff, 0xff, 0xf8, 0x3f, 0xff, 0xff, 0xfc, 0xff, 0xc0, 0x00, 0x07, 0xe0, 0x00, 0x00,
	0xff, 0xff, 0xff, 0xff, 0xf0, 0x3f, 0xff, 0xff, 0xfc, 0xff, 0x80, 0x00, 0x07, 0xc0, 0x00, 0x00,
	0xff, 0xff, 0xff, 0xff, 0xc0, 0x0f, 0xff, 0xff, 0xff, 0x9f, 0xff, 0xff, 0xff, 0x00, 0x00, 0x00,
	0xff, 0xff, 0xff, 0xff, 0x80, 0x0f, 0xff, 0xff, 0xff, 0x9f, 0xff, 0xff, 0xff, 0x00, 0x00, 0x00,
	0xff, 0xff, 0xff, 0xfe, 0x00, 0x0f, 0xff, 0xff, 0xff, 0x9f, 0xff, 0xff, 0xff, 0x00, 0x00, 0x00,
	0xff, 0xff, 0xff, 0xfe, 0x7f, 0xc7, 0xff, 0xff, 0xff, 0x00, 0x00, 0x00, 0x00, 0x00, 0x00, 0x00,
	0xff, 0xff, 0xff, 0xf8, 0x7f, 0xc0, 0x00, 0x00, 0x00, 0x00, 0x00, 0x00, 0x00, 0x00, 0x00, 0x00,
	0xbc, 0x18, 0x7f, 0xfe, 0x7f, 0xf8, 0xf8, 0xfc, 0x00, 0x0f, 0x80, 0x3e, 0x00, 0x00, 0x00, 0x00,
	0x00, 0x00, 0x0f, 0xfc, 0x7e, 0x79, 0xf8, 0xfc, 0x00, 0x1f, 0xc0, 0x7e, 0x00, 0x00, 0x00, 0x00,
	0x00, 0x00, 0x08, 0x04, 0x7e, 0x39, 0xf8, 0xfc, 0x00, 0x1f, 0xc0, 0x7e, 0x00, 0x00, 0x00, 0x00,
	0x00, 0x00, 0x00, 0x00, 0x3e, 0x18, 0x70, 0x38, 0x00, 0x0f, 0x00, 0x3a, 0x00, 0x00, 0x00, 0x00,
	0x00, 0x00, 0x00, 0x00, 0x00, 0x00, 0x00, 0x00, 0x00, 0x00, 0x00, 0x00, 0x00, 0x00, 0x00, 0x00,
	0x00, 0x00, 0x00, 0x00, 0x00, 0x00, 0x38, 0x00, 0x00, 0x00, 0x00, 0x00, 0x00, 0x00, 0x00, 0x00,
	0x00, 0x00, 0x00, 0x00, 0x00, 0x00, 0x3c, 0x00, 0x00, 0x00, 0x00, 0x00, 0x00, 0x00, 0x00, 0x00,
	0x00, 0x00, 0x00, 0x00, 0x00, 0x00, 0x3c, 0x00, 0x00, 0x00, 0x00, 0x00, 0x00, 0x00, 0x00, 0x00,
	0x00, 0x00, 0x00, 0x00, 0x00, 0x00, 0x3c, 0x00, 0x00, 0x00, 0x00, 0x00, 0x00, 0x00, 0x00, 0x00
};
// 'catFrame7', 128x64px
const unsigned char epd_bitmap_catFrame7 []  = {
	0x00, 0x00, 0x00, 0x00, 0x00, 0x00, 0x00, 0x00, 0x00, 0x00, 0x00, 0x00, 0x00, 0x07, 0x80, 0x07,
	0x00, 0x00, 0x00, 0x00, 0x00, 0x00, 0x00, 0x00, 0x00, 0x00, 0x00, 0x00, 0x00, 0x07, 0x80, 0x07,
	0x00, 0x00, 0x00, 0x00, 0x00, 0x00, 0x00, 0x00, 0x00, 0x00, 0x00, 0x00, 0x00, 0x07, 0x80, 0x07,
	0x00, 0x00, 0x00, 0x00, 0x00, 0x00, 0x00, 0x00, 0x00, 0x00, 0x00, 0x00, 0x00, 0x07, 0x80, 0x03,
	0x00, 0x00, 0x00, 0x00, 0x00, 0x00, 0x00, 0x00, 0x00, 0x00, 0x00, 0x00, 0x00, 0x00, 0x00, 0x00,
	0x00, 0x00, 0x00, 0x00, 0x00, 0x00, 0x00, 0x00, 0x00, 0x00, 0x00, 0x00, 0x00, 0x00, 0x00, 0x00,
	0x00, 0x00, 0x00, 0x00, 0x00, 0x00, 0x00, 0x00, 0x00, 0x00, 0x00, 0x00, 0x00, 0x00, 0x00, 0x00,
	0x00, 0x00, 0x00, 0x00, 0x00, 0x00, 0x00, 0x00, 0x00, 0x00, 0x00, 0x00, 0x00, 0x00, 0x07, 0x80,
	0x00, 0x00, 0x00, 0x00, 0x00, 0x00, 0x00, 0x00, 0x00, 0x00, 0x00, 0x00, 0x00, 0x00, 0x07, 0x80,
	0x00, 0x00, 0x00, 0x00, 0x00, 0x00, 0x00, 0x00, 0x00, 0x00, 0x00, 0x00, 0x00, 0x00, 0x07, 0x80,
	0x00, 0x00, 0x00, 0xff, 0xff, 0x00, 0x00, 0x00, 0x00, 0x00, 0x00, 0x00, 0x00, 0x00, 0x07, 0xc0,
	0x00, 0x00, 0x03, 0xff, 0xff, 0xf0, 0x00, 0x00, 0x00, 0x00, 0x00, 0x00, 0x00, 0x00, 0x00, 0x00,
	0xff, 0xff, 0xff, 0xff, 0xff, 0xf8, 0x00, 0x00, 0x00, 0x00, 0x00, 0x00, 0x00, 0x00, 0x00, 0x00,
	0xff, 0xff, 0xff, 0xff, 0xff, 0xcf, 0xff, 0xff, 0xff, 0xff, 0xff, 0xf8, 0x00, 0x00, 0x00, 0x00,
	0xff, 0xff, 0xff, 0xff, 0xff, 0xef, 0xff, 0xff, 0xff, 0xff, 0xff, 0xf8, 0x00, 0x00, 0x00, 0x00,
	0xff, 0xff, 0xff, 0xff, 0xfe, 0x7f, 0xff, 0xff, 0xff, 0xff, 0xff, 0xfe, 0x00, 0x00, 0x00, 0x00,
	0xff, 0xff, 0xff, 0xff, 0xfe, 0x7f, 0xff, 0xff, 0xff, 0xff, 0xff, 0xff, 0x00, 0x00, 0x00, 0x00,
	0xff, 0xff, 0xff, 0xff, 0xfe, 0x7f, 0xff, 0xff, 0xff, 0xff, 0xff, 0xff, 0x00, 0x00, 0x00, 0x00,
	0xff, 0xff, 0xff, 0xff, 0xfe, 0x3f, 0xff, 0xff, 0xff, 0xff, 0xff, 0xff, 0x00, 0x00, 0x00, 0x00,
	0xff, 0xff, 0xff, 0xff, 0xff, 0x7f, 0xff, 0xff, 0xff, 0xff, 0xff, 0xff, 0x00, 0x00, 0x00, 0x00,
	0xff, 0xff, 0xff, 0xff, 0xff, 0x7f, 0xff, 0xff, 0xff, 0xff, 0xff, 0xff, 0x00, 0x00, 0x00, 0x00,
	0xff, 0xff, 0xff, 0xff, 0xfe, 0x7f, 0xff, 0xff, 0xff, 0xff, 0xff, 0xff, 0x00, 0x00, 0x00, 0x00,
	0xff, 0xff, 0xff, 0xff, 0xff, 0x7f, 0xff, 0xff, 0xff, 0xff, 0xff, 0xff, 0x00, 0x00, 0x00, 0x00,
	0xff, 0xff, 0xff, 0xff, 0xff, 0x7f, 0xff, 0xff, 0xff, 0x83, 0xff, 0xff, 0x00, 0x00, 0x00, 0x00,
	0xff, 0xff, 0xff, 0xff, 0xfe, 0x7f, 0xff, 0xff, 0xff, 0x83, 0xff, 0xff, 0x00, 0x00, 0x00, 0x00,
	0xff, 0xff, 0xff, 0xff, 0xff, 0x7f, 0xff, 0xff, 0xff, 0xff, 0xff, 0xff, 0x07, 0xc0, 0x00, 0x00,
	0xff, 0xff, 0xff, 0xff, 0xff, 0x7f, 0xff, 0xff, 0xfc, 0xfe, 0x7f, 0xff, 0x07, 0xc0, 0x00, 0x00,
	0xff, 0xff, 0xff, 0xff, 0xff, 0x7f, 0xff, 0xff, 0xfc, 0xff, 0xff, 0xff, 0x1f, 0xe0, 0x00, 0x00,
	0xff, 0xff, 0xff, 0xff, 0xff, 0x7f, 0xff, 0xff, 0xfc, 0xff, 0x9f, 0xff, 0x3f, 0xc0, 0x00, 0x00,
	0xff, 0xff, 0xff, 0xff, 0xff, 0x7f, 0xff, 0xff, 0xfc, 0xff, 0xdf, 0xff, 0x3f, 0xc0, 0x00, 0x00,
	0xff, 0xff, 0xff, 0xff, 0xff, 0x7f, 0xff, 0xff, 0xfc, 0xff, 0xff, 0xff, 0xff, 0xc0, 0x00, 0x00,
	0xff, 0xff, 0xfe, 0x00, 0x7f, 0x7f, 0xff, 0xff, 0xfc, 0xff, 0xf0, 0x01, 0xff, 0xc0, 0x00, 0x00,
	0xff, 0xff, 0xff, 0x3c, 0x7e, 0x7f, 0xff, 0xff, 0xfc, 0xff, 0xf0, 0x7b, 0xff, 0xe0, 0x00, 0x00,
	0xff, 0xff, 0xf3, 0xfe, 0x00, 0x7f, 0xff, 0xff, 0xfc, 0xff, 0xff, 0xff, 0xff, 0xc0, 0x00, 0x00,
	0xff, 0xff, 0xf3, 0xfe, 0x00, 0x7f, 0xff, 0xff, 0xfc, 0xff, 0xff, 0xff, 0xff, 0xc0, 0x00, 0x00,
	0xff, 0xff, 0xf0, 0xff, 0xf0, 0x7f, 0xff, 0xff, 0xff, 0xff, 0xff, 0xff, 0xff, 0xf8, 0x00, 0x00,
	0xff, 0xff, 0xf0, 0x7f, 0xf0, 0x7f, 0xff, 0xff, 0xe3, 0xff, 0xff, 0xff, 0xff, 0xfc, 0x00, 0x00,
	0xff, 0xff, 0xff, 0xff, 0xf4, 0x7f, 0xff, 0xff, 0xe3, 0xff, 0xff, 0xff, 0xff, 0xfc, 0x00, 0x00,
	0xff, 0xff, 0xff, 0x80, 0x0e, 0x7f, 0xff, 0xff, 0xe3, 0xff, 0xcf, 0xff, 0xf9, 0xfc, 0x00, 0x00,
	0xff, 0xff, 0xff, 0xc0, 0x0e, 0x3f, 0xff, 0xff, 0xe3, 0xff, 0xcf, 0xff, 0xf9, 0xfc, 0x00, 0x00,
	0xff, 0xff, 0xff, 0xff, 0xc0, 0x3f, 0xff, 0xff, 0xe3, 0xff, 0x8f, 0xfb, 0xf9, 0xfc, 0x00, 0x00,
	0xff, 0xff, 0xff, 0xff, 0xc0, 0x7f, 0xff, 0xff, 0xe3, 0xfe, 0x0f, 0xf1, 0xc1, 0xfc, 0x00, 0x00,
	0xff, 0xff, 0xff, 0xff, 0xf0, 0x3f, 0xff, 0xff, 0xe3, 0xfe, 0x1f, 0xfb, 0xc1, 0xfc, 0x00, 0x00,
	0xff, 0xff, 0xff, 0xff, 0xfe, 0x3f, 0xff, 0xff, 0xe3, 0xff, 0xff, 0xff, 0xff, 0xfc, 0x00, 0x00,
	0xff, 0xff, 0xff, 0xff, 0xfe, 0x3f, 0xff, 0xff, 0xe3, 0xff, 0xff, 0xff, 0xff, 0xfc, 0x00, 0x00,
	0xff, 0xff, 0xff, 0xff, 0xfe, 0x3f, 0xff, 0xff, 0xe3, 0xff, 0xcf, 0xcf, 0xc7, 0xfc, 0x00, 0x00,
	0xff, 0xff, 0xff, 0xff, 0xfe, 0x3f, 0xff, 0xff, 0xe3, 0xff, 0x8f, 0xcf, 0xc7, 0xfc, 0x00, 0x00,
	0xff, 0xff, 0xff, 0xff, 0xfe, 0x3f, 0xff, 0xff, 0xff, 0xff, 0xcf, 0xcf, 0xc7, 0xfc, 0x00, 0x00,
	0xff, 0xff, 0xff, 0xff, 0xf0, 0x3f, 0xff, 0xff, 0xfc, 0xff, 0xc0, 0x00, 0x07, 0xe0, 0x00, 0x00,
	0xff, 0xff, 0xff, 0xff, 0xf0, 0x3f, 0xff, 0xff, 0xfc, 0xff, 0x80, 0x00, 0x07, 0xc0, 0x00, 0x00,
	0xff, 0xff, 0xff, 0xff, 0xc0, 0x0f, 0xff, 0xff, 0xff, 0x9f, 0xff, 0xff, 0xff, 0x00, 0x00, 0x00,
	0xff, 0xff, 0xff, 0xff, 0x80, 0x0f, 0xff, 0xff, 0xff, 0x9f, 0xff, 0xff, 0xff, 0x00, 0x00, 0x00,
	0xff, 0xff, 0xff, 0xfe, 0x80, 0x0f, 0xff, 0xff, 0xff, 0x9f, 0xff, 0xff, 0xff, 0x00, 0x00, 0x00,
	0xff, 0xff, 0xff, 0xfe, 0x3f, 0xc6, 0xff, 0xff, 0xfe, 0x00, 0x00, 0x00, 0x00, 0x00, 0x00, 0x00,
	0xff, 0xff, 0xff, 0xf8, 0x7f, 0xc0, 0x00, 0x00, 0x00, 0x00, 0x00, 0x00, 0x00, 0x00, 0x00, 0x00,
	0xff, 0xff, 0xff, 0xfc, 0x7f, 0xc0, 0x30, 0x00, 0x00, 0x0f, 0x00, 0x3e, 0x00, 0x00, 0x00, 0x00,
	0x7f, 0xff, 0xfc, 0x00, 0x7e, 0x01, 0xf8, 0x00, 0x00, 0x1f, 0x80, 0x7e, 0x00, 0x00, 0x00, 0x00,
	0xc0, 0x00, 0x00, 0x00, 0x3e, 0x00, 0xf8, 0x00, 0x00, 0x0f, 0x80, 0x3e, 0x00, 0x00, 0x00, 0x00,
	0x00, 0x00, 0x00, 0x00, 0x00, 0x00, 0x00, 0x00, 0x00, 0x00, 0x00, 0x00, 0x00, 0x00, 0x00, 0x00,
	0x00, 0x00, 0x00, 0x00, 0x00, 0x00, 0x00, 0x00, 0x00, 0x00, 0x00, 0x00, 0x00, 0x00, 0x00, 0x00,
	0x00, 0x00, 0x00, 0x00, 0x00, 0x00, 0x00, 0x00, 0x00, 0x00, 0x00, 0x00, 0x00, 0x00, 0x00, 0x00,
	0x00, 0x00, 0x00, 0x00, 0x00, 0x00, 0x00, 0x00, 0x00, 0x00, 0x00, 0x00, 0x00, 0x00, 0x00, 0x00,
	0x00, 0x00, 0x00, 0x00, 0x00, 0x00, 0x00, 0x00, 0x00, 0x00, 0x00, 0x00, 0x00, 0x00, 0x00, 0x00,
	0x00, 0x00, 0x00, 0x00, 0x00, 0x00, 0x00, 0x00, 0x00, 0x00, 0x00, 0x00, 0x00, 0x00, 0x00, 0x00
};
// 'catFrame6', 128x64px
const unsigned char epd_bitmap_catFrame6 []  = {
	0x00, 0x00, 0x00, 0x00, 0x00, 0x00, 0x00, 0x00, 0x00, 0x00, 0x00, 0x00, 0x00, 0x00, 0x00, 0x00,
	0x00, 0x00, 0x00, 0x00, 0x00, 0x00, 0x00, 0x00, 0x00, 0x00, 0x00, 0x00, 0x00, 0x00, 0x00, 0x00,
	0x00, 0x00, 0x00, 0x00, 0x00, 0x00, 0x00, 0x00, 0x00, 0x00, 0x00, 0x00, 0x00, 0x00, 0x00, 0x00,
	0x00, 0x00, 0x00, 0x00, 0x00, 0x00, 0x00, 0x00, 0x00, 0x00, 0x00, 0x00, 0x00, 0x00, 0x00, 0x00,
	0x00, 0x00, 0x00, 0x00, 0x00, 0x00, 0x00, 0x00, 0x00, 0x00, 0x00, 0x00, 0x00, 0x00, 0x00, 0x00,
	0x00, 0x00, 0x00, 0x00, 0x00, 0x00, 0x00, 0x00, 0x00, 0x00, 0x00, 0x00, 0x00, 0x00, 0x00, 0x00,
	0x00, 0x00, 0x00, 0x00, 0x00, 0x00, 0x00, 0x00, 0x00, 0x00, 0x00, 0x00, 0x00, 0x00, 0x00, 0x00,
	0x00, 0x00, 0x00, 0x00, 0x00, 0x00, 0x00, 0x00, 0x00, 0x00, 0x00, 0x00, 0x00, 0x00, 0x00, 0x00,
	0x00, 0x00, 0x00, 0x00, 0x00, 0x00, 0x00, 0x00, 0x00, 0x00, 0x00, 0x00, 0x00, 0x00, 0x00, 0x00,
	0xf5, 0x5e, 0x80, 0x00, 0x00, 0x00, 0x00, 0x00, 0x00, 0x00, 0x00, 0x00, 0x00, 0x00, 0x00, 0x00,
	0x22, 0x02, 0x00, 0x00, 0x00, 0x00, 0x00, 0x00, 0x00, 0x00, 0x00, 0x00, 0x00, 0x00, 0x00, 0x00,
	0x00, 0x00, 0x24, 0x01, 0x80, 0x00, 0x00, 0x00, 0x00, 0x00, 0x00, 0x00, 0x00, 0x00, 0x00, 0x00,
	0xff, 0xff, 0xe0, 0x00, 0x00, 0x00, 0x00, 0x00, 0x00, 0x00, 0x00, 0x00, 0x00, 0x00, 0x00, 0x00,
	0xff, 0xff, 0xff, 0xff, 0xfe, 0x0f, 0xff, 0xff, 0xff, 0xff, 0xff, 0xf8, 0x00, 0x00, 0x00, 0x00,
	0xff, 0xff, 0xfb, 0xae, 0xee, 0x0f, 0xff, 0xff, 0xff, 0xff, 0xff, 0xf8, 0x00, 0x00, 0x00, 0x00,
	0xff, 0xff, 0xff, 0xff, 0xfc, 0x3f, 0xff, 0xff, 0xff, 0xff, 0xff, 0xff, 0x00, 0x00, 0x00, 0x00,
	0xff, 0xff, 0xff, 0xff, 0xf8, 0x3f, 0xff, 0xff, 0xff, 0xff, 0xff, 0xff, 0x00, 0x00, 0x00, 0x00,
	0xff, 0xff, 0xff, 0xff, 0xfc, 0x3f, 0xff, 0xff, 0xff, 0xff, 0xff, 0xff, 0x00, 0x00, 0x00, 0x00,
	0xff, 0xff, 0xf5, 0xff, 0xf0, 0x3f, 0xff, 0xff, 0xff, 0xff, 0xff, 0xff, 0x00, 0x00, 0x00, 0x00,
	0xff, 0xff, 0xfb, 0xfe, 0xf8, 0x3f, 0xff, 0xff, 0xff, 0xff, 0xff, 0xff, 0x00, 0x00, 0x00, 0x00,
	0xff, 0xff, 0xff, 0xff, 0xfe, 0x3f, 0xff, 0xff, 0xff, 0xff, 0xff, 0xff, 0x00, 0x00, 0x00, 0x00,
	0xff, 0xff, 0xff, 0xff, 0xfe, 0x3f, 0xff, 0xff, 0xff, 0xff, 0xff, 0xff, 0x00, 0x00, 0x00, 0x00,
	0xff, 0xff, 0xff, 0xff, 0xfe, 0x3f, 0xff, 0xff, 0xff, 0xff, 0xff, 0xff, 0x00, 0x00, 0x00, 0x00,
	0xff, 0xff, 0xff, 0xff, 0xfe, 0x3f, 0xff, 0xff, 0xff, 0xf0, 0x7f, 0xff, 0x00, 0x00, 0x00, 0x00,
	0xff, 0xff, 0xff, 0xff, 0xfe, 0x3f, 0xff, 0xff, 0xff, 0xf0, 0x7f, 0xff, 0x00, 0x00, 0x00, 0x00,
	0xff, 0xff, 0xff, 0xff, 0xfe, 0x3f, 0xff, 0xff, 0xff, 0xff, 0xff, 0xff, 0x00, 0xfc, 0x00, 0x00,
	0xff, 0xff, 0xff, 0xff, 0xfe, 0x3f, 0xff, 0xff, 0xff, 0xdf, 0x8f, 0xff, 0x00, 0xfc, 0x00, 0x00,
	0xff, 0xff, 0xff, 0xff, 0xfe, 0x3f, 0xff, 0xff, 0xff, 0x9f, 0xff, 0xff, 0x07, 0xfc, 0x00, 0x00,
	0xff, 0xff, 0xff, 0xff, 0xff, 0x7f, 0xff, 0xff, 0xff, 0xdf, 0xf3, 0xff, 0x07, 0xfc, 0x00, 0x00,
	0xff, 0xff, 0xff, 0xff, 0xff, 0x3f, 0xff, 0xff, 0xff, 0x9f, 0xf3, 0xfe, 0x07, 0xfc, 0x00, 0x00,
	0xff, 0xff, 0xff, 0xff, 0xff, 0x3f, 0xff, 0xff, 0xff, 0x9f, 0xff, 0xfe, 0x3f, 0xfc, 0x00, 0x00,
	0xff, 0xff, 0xff, 0xff, 0xff, 0x7f, 0xff, 0xff, 0xff, 0x9f, 0xfe, 0x00, 0x3f, 0xfc, 0x00, 0x00,
	0xff, 0xff, 0xff, 0xff, 0xff, 0x3f, 0xff, 0xff, 0xff, 0x9f, 0xfe, 0xff, 0xff, 0xfc, 0x00, 0x00,
	0xff, 0xff, 0xff, 0xff, 0xff, 0x3f, 0xff, 0xff, 0xff, 0x9f, 0xff, 0xff, 0xff, 0xfc, 0x00, 0x00,
	0xff, 0xff, 0xff, 0xff, 0xff, 0x3f, 0xff, 0xff, 0xff, 0x9f, 0xff, 0xff, 0xff, 0xfc, 0x00, 0x00,
	0xff, 0xff, 0xff, 0xff, 0xfe, 0x7f, 0xff, 0xff, 0xff, 0xff, 0xff, 0xff, 0xff, 0xff, 0x00, 0x00,
	0xff, 0xff, 0xff, 0xff, 0xc0, 0x3f, 0xff, 0xff, 0xfe, 0x7f, 0xff, 0xff, 0xff, 0xff, 0x00, 0x00,
	0xff, 0xff, 0xff, 0xff, 0xc0, 0x3f, 0xff, 0xff, 0xfc, 0x7f, 0xff, 0xff, 0xff, 0xff, 0x80, 0x00,
	0xff, 0xff, 0xff, 0xfe, 0x7e, 0x3f, 0xff, 0xff, 0xfc, 0x7f, 0xfb, 0xff, 0xff, 0x3f, 0x80, 0x00,
	0xff, 0xff, 0xff, 0xf0, 0x7e, 0x3f, 0xff, 0xff, 0xfc, 0x7f, 0xfb, 0xff, 0xff, 0x3f, 0x80, 0x00,
	0xff, 0xff, 0xff, 0xdf, 0xfe, 0x3f, 0xff, 0xff, 0xfc, 0x7f, 0xf3, 0xff, 0x7f, 0x3f, 0x80, 0x00,
	0xff, 0xff, 0xff, 0xdf, 0xfe, 0x3f, 0xff, 0xff, 0xfc, 0x7f, 0x83, 0xfe, 0x38, 0x3f, 0x80, 0x00,
	0xff, 0xff, 0xff, 0xff, 0xfe, 0x3f, 0xff, 0xff, 0xfc, 0x7f, 0xc3, 0xff, 0x7d, 0xbf, 0x00, 0x00,
	0xff, 0xff, 0xfc, 0x7e, 0x00, 0x3f, 0xff, 0xff, 0xfc, 0x7f, 0xff, 0xff, 0xff, 0xff, 0x80, 0x00,
	0xff, 0xff, 0xfc, 0x7e, 0x00, 0x3f, 0xff, 0xff, 0xfc, 0x7f, 0xff, 0xff, 0xff, 0xff, 0x00, 0x00,
	0xff, 0xff, 0xfc, 0x7e, 0x00, 0x3f, 0xff, 0xff, 0xfc, 0x7f, 0xfb, 0xfb, 0xf9, 0xff, 0x80, 0x00,
	0xff, 0xff, 0xfc, 0x7e, 0x3e, 0x3f, 0xff, 0xff, 0xfc, 0x7f, 0xf1, 0xf9, 0xf8, 0xff, 0x00, 0x00,
	0xff, 0xff, 0xfe, 0x7e, 0x7e, 0x3f, 0xff, 0xff, 0xff, 0xff, 0xf1, 0xf9, 0xf8, 0xff, 0x00, 0x00,
	0xff, 0xff, 0xff, 0xa9, 0xfe, 0x3f, 0xff, 0xff, 0xff, 0x9f, 0xf0, 0x00, 0x00, 0xfc, 0x00, 0x00,
	0xff, 0xff, 0xff, 0x81, 0xfe, 0x3f, 0xff, 0xff, 0xff, 0x9f, 0xf0, 0x00, 0x00, 0xfc, 0x00, 0x00,
	0xff, 0xff, 0xff, 0xff, 0xfe, 0x1f, 0xff, 0xff, 0xff, 0xf3, 0xff, 0xff, 0xff, 0xe0, 0x00, 0x00,
	0xff, 0xff, 0xff, 0xff, 0xfe, 0x0f, 0xff, 0xff, 0xff, 0xf3, 0xff, 0xff, 0xff, 0xe0, 0x00, 0x00,
	0xff, 0xff, 0xff, 0xff, 0xfe, 0x0f, 0xff, 0xff, 0xff, 0xf3, 0xff, 0xff, 0xff, 0xc0, 0x00, 0x00,
	0xff, 0xff, 0xff, 0xff, 0xf1, 0xff, 0xbf, 0xbd, 0xfa, 0xe0, 0x00, 0x00, 0x00, 0x00, 0x00, 0x00,
	0xff, 0xff, 0xff, 0xff, 0xf1, 0xf8, 0x00, 0x00, 0x00, 0x00, 0x00, 0x00, 0x00, 0x00, 0x00, 0x00,
	0xf7, 0xff, 0xff, 0xff, 0xf1, 0xf8, 0x03, 0xc0, 0x00, 0x00, 0x3c, 0x01, 0xf8, 0x00, 0x00, 0x00,
	0x00, 0x00, 0x1f, 0xff, 0xf1, 0xf8, 0x07, 0xe0, 0x00, 0x00, 0x7e, 0x01, 0xf8, 0x00, 0x00, 0x00,
	0x00, 0x00, 0x07, 0xff, 0xc1, 0xf0, 0x07, 0xc0, 0x00, 0x00, 0x7e, 0x11, 0xf8, 0x00, 0x00, 0x00,
	0x00, 0x00, 0x00, 0x00, 0x00, 0x00, 0x00, 0x00, 0x00, 0x00, 0x00, 0x00, 0x00, 0x00, 0x00, 0x00,
	0x00, 0x00, 0x00, 0x00, 0x00, 0x00, 0x00, 0x00, 0x00, 0x00, 0x00, 0x00, 0x00, 0x00, 0x00, 0x00,
	0x00, 0x00, 0x00, 0x00, 0x00, 0x00, 0x00, 0x00, 0x00, 0x00, 0x00, 0x00, 0x00, 0x00, 0x00, 0x00,
	0x00, 0x00, 0x00, 0x00, 0x00, 0x00, 0x00, 0x00, 0x00, 0x00, 0x00, 0x00, 0x00, 0x00, 0x00, 0x00,
	0x00, 0x00, 0x00, 0x00, 0x00, 0x00, 0x00, 0x00, 0x00, 0x00, 0x00, 0x00, 0x00, 0x00, 0x00, 0x00,
	0x00, 0x00, 0x00, 0x00, 0x00, 0x00, 0x00, 0x00, 0x00, 0x00, 0x00, 0x00, 0x00, 0x00, 0x00, 0x00
};
// 'catFrame5', 128x64px
const unsigned char epd_bitmap_catFrame5 []  = {
	0x00, 0x00, 0x00, 0x00, 0x00, 0x00, 0x00, 0x00, 0x00, 0x00, 0x00, 0x00, 0x00, 0x00, 0x00, 0x00,
	0x00, 0x00, 0x00, 0x00, 0x00, 0x00, 0x00, 0x00, 0x00, 0x00, 0x00, 0x00, 0x00, 0x00, 0x00, 0x00,
	0x00, 0x00, 0x00, 0x00, 0x00, 0x00, 0x00, 0x00, 0x00, 0x00, 0x00, 0x00, 0x00, 0x00, 0x00, 0x00,
	0x00, 0x00, 0x00, 0x00, 0x00, 0x00, 0x00, 0x00, 0x00, 0x00, 0x00, 0x00, 0x00, 0x00, 0x00, 0x00,
	0x00, 0x00, 0x00, 0x00, 0x00, 0x00, 0x00, 0x00, 0x00, 0x00, 0x00, 0x00, 0x00, 0x00, 0x00, 0x00,
	0x00, 0x00, 0x00, 0x00, 0x00, 0x00, 0x00, 0x00, 0x00, 0x00, 0x00, 0x00, 0x00, 0x00, 0x00, 0x00,
	0x00, 0x00, 0x00, 0x00, 0x00, 0x00, 0x00, 0x00, 0x00, 0x00, 0x00, 0x00, 0x00, 0x00, 0x00, 0x00,
	0x00, 0x00, 0x00, 0x00, 0x00, 0x00, 0x00, 0x00, 0x00, 0x00, 0x00, 0x00, 0x00, 0x00, 0x00, 0x00,
	0x00, 0x00, 0x00, 0x00, 0x00, 0x00, 0x00, 0x00, 0x00, 0x00, 0x00, 0x00, 0x00, 0x00, 0x00, 0x00,
	0x00, 0x00, 0x00, 0x00, 0x00, 0x00, 0x00, 0x00, 0x00, 0x00, 0x00, 0x00, 0x00, 0x00, 0x00, 0x00,
	0x00, 0x00, 0x01, 0xff, 0xff, 0xcf, 0xff, 0xff, 0xff, 0xff, 0xff, 0xf8, 0x00, 0x00, 0x00, 0x00,
	0x00, 0x00, 0x07, 0xff, 0xff, 0xcf, 0xff, 0xff, 0xff, 0xff, 0xff, 0xf8, 0x00, 0x00, 0x00, 0x00,
	0xff, 0xff, 0xff, 0xff, 0xff, 0xff, 0xff, 0xff, 0xff, 0xff, 0xff, 0xfe, 0x00, 0x00, 0x00, 0x00,
	0xff, 0xff, 0xff, 0xff, 0xff, 0x3f, 0xff, 0xff, 0xff, 0xff, 0xff, 0xfe, 0x00, 0x00, 0x00, 0x00,
	0xff, 0xff, 0xff, 0xff, 0xfe, 0x3f, 0xff, 0xff, 0xff, 0xff, 0xff, 0xff, 0x00, 0x00, 0x00, 0x00,
	0xff, 0xff, 0xff, 0xff, 0xfe, 0x3f, 0xff, 0xff, 0xff, 0xff, 0xff, 0xfe, 0x00, 0x00, 0x00, 0x00,
	0xff, 0xff, 0xff, 0xff, 0xfe, 0x3f, 0xff, 0xff, 0xff, 0xff, 0xff, 0xfe, 0x00, 0x00, 0x00, 0x00,
	0xff, 0xff, 0xff, 0xff, 0xfe, 0x3f, 0xff, 0xff, 0xff, 0xff, 0xff, 0xfe, 0x00, 0x00, 0x00, 0x00,
	0xff, 0xff, 0xff, 0xff, 0xff, 0x3f, 0xff, 0xff, 0xff, 0xff, 0xff, 0xfe, 0x00, 0x00, 0x00, 0x00,
	0xff, 0xff, 0xff, 0xff, 0xfe, 0x3f, 0xff, 0xff, 0xff, 0xff, 0xff, 0xfe, 0x00, 0x00, 0x00, 0x00,
	0xff, 0xff, 0xff, 0xff, 0xfe, 0x3f, 0xff, 0xff, 0xff, 0xff, 0xff, 0xfe, 0x00, 0x00, 0x00, 0x00,
	0xff, 0xff, 0xff, 0xff, 0xfe, 0x3f, 0xff, 0xff, 0xff, 0x83, 0xff, 0xfe, 0x00, 0x00, 0x00, 0x00,
	0xff, 0xff, 0xff, 0xff, 0xfe, 0x3f, 0xff, 0xff, 0xff, 0x83, 0xff, 0xfe, 0x00, 0x40, 0x00, 0x00,
	0xff, 0xff, 0xff, 0xff, 0xfe, 0x3f, 0xff, 0xff, 0xfc, 0x7c, 0x7f, 0xfe, 0x07, 0xc0, 0x00, 0x00,
	0xff, 0xff, 0xff, 0xff, 0xfe, 0x3f, 0xff, 0xff, 0xfc, 0x7e, 0x7f, 0xff, 0x07, 0xc0, 0x00, 0x00,
	0xff, 0xff, 0xff, 0xff, 0xff, 0x3f, 0xff, 0xff, 0xfc, 0x7f, 0xff, 0xfe, 0x3f, 0xe0, 0x00, 0x00,
	0xff, 0xff, 0xfe, 0x00, 0x7f, 0x3f, 0xff, 0xff, 0xfc, 0x7f, 0x8f, 0xff, 0x3f, 0xc0, 0x00, 0x00,
	0xff, 0xff, 0xfe, 0x00, 0x7f, 0x3f, 0xff, 0xff, 0xfc, 0x7f, 0x9f, 0xfe, 0x3f, 0xc0, 0x00, 0x00,
	0xff, 0xff, 0xfe, 0x7e, 0x1f, 0x3f, 0xff, 0xff, 0xfc, 0x7f, 0xf0, 0x01, 0xff, 0xc0, 0x00, 0x00,
	0xff, 0xff, 0xfe, 0x7e, 0x0f, 0x3f, 0xff, 0xff, 0xfc, 0x7f, 0xf0, 0x01, 0xff, 0xc0, 0x00, 0x00,
	0xff, 0xff, 0xfe, 0x1f, 0x8e, 0x3f, 0xff, 0xff, 0xfc, 0x7f, 0xff, 0xff, 0xff, 0xc0, 0x00, 0x00,
	0xff, 0xff, 0xfe, 0x0f, 0xc0, 0x3f, 0xff, 0xff, 0xfc, 0x7f, 0xff, 0xff, 0xff, 0xe0, 0x00, 0x00,
	0xff, 0xff, 0xfe, 0x0f, 0xc0, 0x3f, 0xff, 0xff, 0xfc, 0xff, 0xff, 0xff, 0xff, 0xe0, 0x00, 0x00,
	0xff, 0xff, 0xff, 0x81, 0xf0, 0x3f, 0xff, 0xff, 0xe3, 0xff, 0xff, 0xff, 0xff, 0xf8, 0x00, 0x00,
	0xff, 0xff, 0xff, 0x81, 0xf0, 0x3f, 0xff, 0xff, 0xe3, 0xff, 0xff, 0xff, 0xff, 0xfc, 0x00, 0x00,
	0xff, 0xff, 0xff, 0xf1, 0xfe, 0x3f, 0xff, 0xff, 0xe3, 0xff, 0xff, 0xff, 0xff, 0xf8, 0x00, 0x00,
	0xff, 0xff, 0xff, 0xf0, 0x3e, 0x3f, 0xff, 0xff, 0xe3, 0xff, 0xcf, 0xff, 0xf9, 0xf8, 0x00, 0x00,
	0xff, 0xff, 0xff, 0xf0, 0x3e, 0x3f, 0xff, 0xff, 0xe3, 0xff, 0xcf, 0xff, 0xf9, 0xf8, 0x00, 0x00,
	0xff, 0xff, 0xff, 0xfe, 0x00, 0x3f, 0xff, 0xff, 0xe3, 0xfe, 0x0f, 0xf9, 0xc1, 0xf8, 0x00, 0x00,
	0xff, 0xff, 0xff, 0xfe, 0x00, 0x3f, 0xff, 0xff, 0xe3, 0xfe, 0x0f, 0xf1, 0xc1, 0xfc, 0x00, 0x00,
	0xff, 0xff, 0xff, 0xff, 0xf0, 0x3f, 0xff, 0xff, 0xe3, 0xff, 0xff, 0xff, 0xff, 0xf8, 0x00, 0x00,
	0xff, 0xff, 0xff, 0xff, 0xf0, 0x3f, 0xff, 0xff, 0xe3, 0xff, 0xff, 0xff, 0xff, 0xfc, 0x00, 0x00,
	0xff, 0xff, 0xff, 0xff, 0xf0, 0x3f, 0xff, 0xff, 0xe3, 0xff, 0xff, 0xff, 0xff, 0xfc, 0x00, 0x00,
	0xff, 0xff, 0xff, 0xff, 0xfe, 0x3f, 0xff, 0xff, 0xe3, 0xff, 0x8f, 0xcf, 0xc7, 0xfc, 0x00, 0x00,
	0xff, 0xff, 0xff, 0xff, 0xfe, 0x3f, 0xff, 0xff, 0xe3, 0xff, 0x8f, 0xcf, 0xc7, 0xfc, 0x00, 0x00,
	0xff, 0xff, 0xff, 0xff, 0xfe, 0x3f, 0xff, 0xff, 0xfd, 0xff, 0x87, 0x87, 0xc7, 0xf8, 0x00, 0x00,
	0xff, 0xff, 0xff, 0xff, 0xfe, 0x3f, 0xff, 0xff, 0xfc, 0x7f, 0x80, 0x00, 0x07, 0xe0, 0x00, 0x00,
	0xff, 0xff, 0xff, 0xff, 0xfc, 0x3f, 0xff, 0xff, 0xff, 0xff, 0xc0, 0x00, 0x07, 0xc0, 0x00, 0x00,
	0xff, 0xff, 0xff, 0xff, 0xf0, 0x0f, 0xff, 0xff, 0xff, 0x9f, 0xff, 0xff, 0xff, 0x00, 0x00, 0x00,
	0xff, 0xff, 0xff, 0xff, 0xf0, 0x0f, 0xff, 0xff, 0xff, 0x9f, 0xff, 0xff, 0xff, 0x00, 0x00, 0x00,
	0xff, 0xff, 0xff, 0xff, 0xc7, 0xfa, 0x04, 0x18, 0x04, 0x00, 0x00, 0x00, 0x00, 0x00, 0x00, 0x00,
	0xff, 0xff, 0xff, 0xff, 0x8f, 0xf8, 0x00, 0x00, 0x00, 0x00, 0x00, 0x00, 0x00, 0x00, 0x00, 0x00,
	0xff, 0xff, 0xff, 0xff, 0x8f, 0xf0, 0x00, 0x00, 0x00, 0x00, 0x00, 0x00, 0x00, 0x00, 0x00, 0x00,
	0xff, 0xff, 0xff, 0xff, 0x8f, 0xc0, 0x07, 0xc0, 0x00, 0x03, 0xf0, 0x07, 0xc0, 0x00, 0x00, 0x00,
	0xff, 0xff, 0xff, 0xff, 0x8f, 0xc0, 0x07, 0xe0, 0x00, 0x03, 0xf0, 0x07, 0xc0, 0x00, 0x00, 0x00,
	0xff, 0xff, 0xff, 0xff, 0x0f, 0x80, 0x03, 0xe0, 0x00, 0x03, 0xf0, 0x07, 0xc0, 0x00, 0x00, 0x00,
	0xff, 0xff, 0xfc, 0x00, 0x00, 0x00, 0x00, 0x00, 0x00, 0x00, 0x00, 0x00, 0x00, 0x00, 0x00, 0x00,
	0xff, 0xff, 0xf8, 0x00, 0x00, 0x00, 0x00, 0x00, 0x00, 0x00, 0x00, 0x00, 0x00, 0x00, 0x00, 0x00,
	0x00, 0x00, 0x00, 0x00, 0x00, 0x00, 0x00, 0x00, 0x00, 0x00, 0x00, 0x00, 0x00, 0x00, 0x00, 0x00,
	0x00, 0x00, 0x00, 0x00, 0x00, 0x00, 0x00, 0x00, 0x00, 0x00, 0x00, 0x00, 0x00, 0x00, 0x00, 0x00,
	0x00, 0x00, 0x00, 0x00, 0x00, 0x00, 0x00, 0x00, 0x00, 0x00, 0x00, 0x00, 0x00, 0x00, 0x00, 0x00,
	0x00, 0x00, 0x00, 0x00, 0x00, 0x00, 0x00, 0x00, 0x00, 0x00, 0x00, 0x00, 0x00, 0x00, 0x00, 0x00,
	0xc0, 0x00, 0x00, 0x00, 0x00, 0x00, 0x00, 0x00, 0x00, 0x00, 0x00, 0x00, 0x00, 0x00, 0x00, 0x00,
	0xe0, 0x00, 0x00, 0x00, 0x00, 0x00, 0x00, 0x00, 0x00, 0x00, 0x00, 0x00, 0x00, 0x00, 0x00, 0x00
};

void SystemClock_Config(void);
static void MX_GPIO_Init(void);
static void MX_USART2_UART_Init(void);
static void MX_I2C1_Init(void);
static void MX_TIM2_Init(void);
void StartBlinker(void *argument);
void StartOled(void *argument);

int main(void)
{

  /* MCU Configuration--------------------------------------------------------*/

  /* Reset of all peripherals, Initializes the Flash interface and the Systick. */
  HAL_Init();

  /* Configure the system clock */
  SystemClock_Config();

  /* Initialize all configured peripherals */
  MX_GPIO_Init();
  MX_USART2_UART_Init();
  MX_I2C1_Init();
  MX_TIM2_Init();
  /* USER CODE BEGIN 2 */
  ssd1306_Init();
  HAL_TIM_PWM_Start(&htim2, TIM_CHANNEL_1);
  /* USER CODE END 2 */

  /* Init scheduler */
  osKernelInitialize();

  /* Create the thread(s) */
  /* creation of blinker */
  blinkerHandle = osThreadNew(StartBlinker, NULL, &blinker_attributes);

  /* creation of oled */
  oledHandle = osThreadNew(StartOled, NULL, &oled_attributes);

  /* Start scheduler */
  osKernelStart();

  /* We should never get here as control is now taken by the scheduler */
  /* Infinite loop */
  while (1)
  {

  }
}

void SystemClock_Config(void)
{
  RCC_OscInitTypeDef RCC_OscInitStruct = {0};
  RCC_ClkInitTypeDef RCC_ClkInitStruct = {0};

  /** Configure the main internal regulator output voltage
  */
  __HAL_RCC_PWR_CLK_ENABLE();
  __HAL_PWR_VOLTAGESCALING_CONFIG(PWR_REGULATOR_VOLTAGE_SCALE3);

  /** Initializes the RCC Oscillators according to the specified parameters
  * in the RCC_OscInitTypeDef structure.
  */
  RCC_OscInitStruct.OscillatorType = RCC_OSCILLATORTYPE_HSI;
  RCC_OscInitStruct.HSIState = RCC_HSI_ON;
  RCC_OscInitStruct.HSICalibrationValue = RCC_HSICALIBRATION_DEFAULT;
  RCC_OscInitStruct.PLL.PLLState = RCC_PLL_ON;
  RCC_OscInitStruct.PLL.PLLSource = RCC_PLLSOURCE_HSI;
  RCC_OscInitStruct.PLL.PLLM = 16;
  RCC_OscInitStruct.PLL.PLLN = 336;
  RCC_OscInitStruct.PLL.PLLP = RCC_PLLP_DIV4;
  RCC_OscInitStruct.PLL.PLLQ = 2;
  RCC_OscInitStruct.PLL.PLLR = 2;
  if (HAL_RCC_OscConfig(&RCC_OscInitStruct) != HAL_OK)
  {
    Error_Handler();
  }

  /** Initializes the CPU, AHB and APB buses clocks
  */
  RCC_ClkInitStruct.ClockType = RCC_CLOCKTYPE_HCLK|RCC_CLOCKTYPE_SYSCLK
                              |RCC_CLOCKTYPE_PCLK1|RCC_CLOCKTYPE_PCLK2;
  RCC_ClkInitStruct.SYSCLKSource = RCC_SYSCLKSOURCE_PLLCLK;
  RCC_ClkInitStruct.AHBCLKDivider = RCC_SYSCLK_DIV1;
  RCC_ClkInitStruct.APB1CLKDivider = RCC_HCLK_DIV2;
  RCC_ClkInitStruct.APB2CLKDivider = RCC_HCLK_DIV1;

  if (HAL_RCC_ClockConfig(&RCC_ClkInitStruct, FLASH_LATENCY_2) != HAL_OK)
  {
    Error_Handler();
  }
}

static void MX_I2C1_Init(void)
{

  hi2c1.Instance = I2C1;
  hi2c1.Init.ClockSpeed = 400000;
  hi2c1.Init.DutyCycle = I2C_DUTYCYCLE_2;
  hi2c1.Init.OwnAddress1 = 0;
  hi2c1.Init.AddressingMode = I2C_ADDRESSINGMODE_7BIT;
  hi2c1.Init.DualAddressMode = I2C_DUALADDRESS_DISABLE;
  hi2c1.Init.OwnAddress2 = 0;
  hi2c1.Init.GeneralCallMode = I2C_GENERALCALL_DISABLE;
  hi2c1.Init.NoStretchMode = I2C_NOSTRETCH_DISABLE;
  if (HAL_I2C_Init(&hi2c1) != HAL_OK)
  {
    Error_Handler();
  }

}

static void MX_TIM2_Init(void)
{

  TIM_ClockConfigTypeDef sClockSourceConfig = {0};
  TIM_MasterConfigTypeDef sMasterConfig = {0};
  TIM_OC_InitTypeDef sConfigOC = {0};

  htim2.Instance = TIM2;
  htim2.Init.Prescaler = 0;
  htim2.Init.CounterMode = TIM_COUNTERMODE_UP;
  htim2.Init.Period = 255;
  htim2.Init.ClockDivision = TIM_CLOCKDIVISION_DIV1;
  htim2.Init.AutoReloadPreload = TIM_AUTORELOAD_PRELOAD_ENABLE;
  if (HAL_TIM_Base_Init(&htim2) != HAL_OK)
  {
    Error_Handler();
  }
  sClockSourceConfig.ClockSource = TIM_CLOCKSOURCE_INTERNAL;
  if (HAL_TIM_ConfigClockSource(&htim2, &sClockSourceConfig) != HAL_OK)
  {
    Error_Handler();
  }
  if (HAL_TIM_PWM_Init(&htim2) != HAL_OK)
  {
    Error_Handler();
  }
  sMasterConfig.MasterOutputTrigger = TIM_TRGO_RESET;
  sMasterConfig.MasterSlaveMode = TIM_MASTERSLAVEMODE_DISABLE;
  if (HAL_TIMEx_MasterConfigSynchronization(&htim2, &sMasterConfig) != HAL_OK)
  {
    Error_Handler();
  }
  sConfigOC.OCMode = TIM_OCMODE_PWM1;
  sConfigOC.Pulse = 123;
  sConfigOC.OCPolarity = TIM_OCPOLARITY_HIGH;
  sConfigOC.OCFastMode = TIM_OCFAST_DISABLE;
  if (HAL_TIM_PWM_ConfigChannel(&htim2, &sConfigOC, TIM_CHANNEL_1) != HAL_OK)
  {
    Error_Handler();
  }
  HAL_TIM_MspPostInit(&htim2);

}

static void MX_USART2_UART_Init(void)
{

  huart2.Instance = USART2;
  huart2.Init.BaudRate = 115200;
  huart2.Init.WordLength = UART_WORDLENGTH_8B;
  huart2.Init.StopBits = UART_STOPBITS_1;
  huart2.Init.Parity = UART_PARITY_NONE;
  huart2.Init.Mode = UART_MODE_TX_RX;
  huart2.Init.HwFlowCtl = UART_HWCONTROL_NONE;
  huart2.Init.OverSampling = UART_OVERSAMPLING_16;
  if (HAL_UART_Init(&huart2) != HAL_OK)
  {
    Error_Handler();
  }

}

static void MX_GPIO_Init(void)
{
  GPIO_InitTypeDef GPIO_InitStruct = {0};

  /* GPIO Ports Clock Enable */
  __HAL_RCC_GPIOC_CLK_ENABLE();
  __HAL_RCC_GPIOH_CLK_ENABLE();
  __HAL_RCC_GPIOA_CLK_ENABLE();
  __HAL_RCC_GPIOB_CLK_ENABLE();

  /*Configure GPIO pin Output Level */
  HAL_GPIO_WritePin(GPIOA, LD2_Pin|GPIO_PIN_8, GPIO_PIN_RESET);

  /*Configure GPIO pin : B1_Pin */
  GPIO_InitStruct.Pin = B1_Pin;
  GPIO_InitStruct.Mode = GPIO_MODE_IT_FALLING;
  GPIO_InitStruct.Pull = GPIO_NOPULL;
  HAL_GPIO_Init(B1_GPIO_Port, &GPIO_InitStruct);

  /*Configure GPIO pins : LD2_Pin PA8 */
  GPIO_InitStruct.Pin = LD2_Pin|GPIO_PIN_8;
  GPIO_InitStruct.Mode = GPIO_MODE_OUTPUT_PP;
  GPIO_InitStruct.Pull = GPIO_NOPULL;
  GPIO_InitStruct.Speed = GPIO_SPEED_FREQ_LOW;
  HAL_GPIO_Init(GPIOA, &GPIO_InitStruct);

}

void StartBlinker(void *argument)
{
  /* USER CODE BEGIN 5 */
	int pulse=0;
  /* Infinite loop */
  for(;;)
  {
//	  	  HAL_GPIO_WritePin(GPIOA, GPIO_PIN_8, 1);
//	  	  HAL_GPIO_WritePin(GPIOA, GPIO_PIN_5, 1);
//	      osDelay(500);
//	      HAL_GPIO_WritePin(GPIOA, GPIO_PIN_5, 0);
//	  	  HAL_GPIO_WritePin(GPIOA, GPIO_PIN_8, 0);
//	  	  osDelay(500);
	        pulse++;
	        if(pulse/256==1)pulse=0;
	        __HAL_TIM_SET_COMPARE(&htim2,TIM_CHANNEL_1,pulse);
	        osDelay(10);

  }
  osThreadTerminate(NULL);
  /* USER CODE END 5 */
}

void StartOled(void *argument)
{
  /* USER CODE BEGIN StartOled */
  /* Infinite loop */
  for(;;)
  {
	  ssd1306_Fill(Black);
	      ssd1306_DrawBitmap(0,0,epd_bitmap_catFrame0,128,64,White);
	      osDelay(100);
	      ssd1306_UpdateScreen();
	      ssd1306_Fill(Black);
	          ssd1306_DrawBitmap(0,0,epd_bitmap_catFrame1,128,64,White);
	          osDelay(100);
	          ssd1306_UpdateScreen();
	          ssd1306_Fill(Black);
	              ssd1306_DrawBitmap(0,0,epd_bitmap_catFrame2,128,64,White);
	              osDelay(100);
	              ssd1306_UpdateScreen();
	              ssd1306_Fill(Black);
	                  ssd1306_DrawBitmap(0,0,epd_bitmap_catFrame3,128,64,White);
	                  osDelay(100);
	                  ssd1306_UpdateScreen();
	                  ssd1306_Fill(Black);
	                      ssd1306_DrawBitmap(0,0,epd_bitmap_catFrame4,128,64,White);
	                      osDelay(100);
	                      ssd1306_UpdateScreen();
	                      ssd1306_Fill(Black);
	                          ssd1306_DrawBitmap(0,0,epd_bitmap_catFrame5,128,64,White);
	                          osDelay(100);
	                          ssd1306_UpdateScreen();
	                          ssd1306_Fill(Black);
	                              ssd1306_DrawBitmap(0,0,epd_bitmap_catFrame6,128,64,White);
	                              osDelay(100);
	                              ssd1306_UpdateScreen();
	                              ssd1306_Fill(Black);
	                                  ssd1306_DrawBitmap(0,0,epd_bitmap_catFrame7,128,64,White);
	                                  osDelay(100);
	                                  ssd1306_UpdateScreen();
	  osDelay(1);

  }
  osThreadTerminate(NULL);
  /* USER CODE END StartOled */
}

void HAL_TIM_PeriodElapsedCallback(TIM_HandleTypeDef *htim)
{
  if (htim->Instance == TIM6) {
    HAL_IncTick();
  }
}

void Error_Handler(void)
{
  __disable_irq();
  while (1)
  {
  }
}
